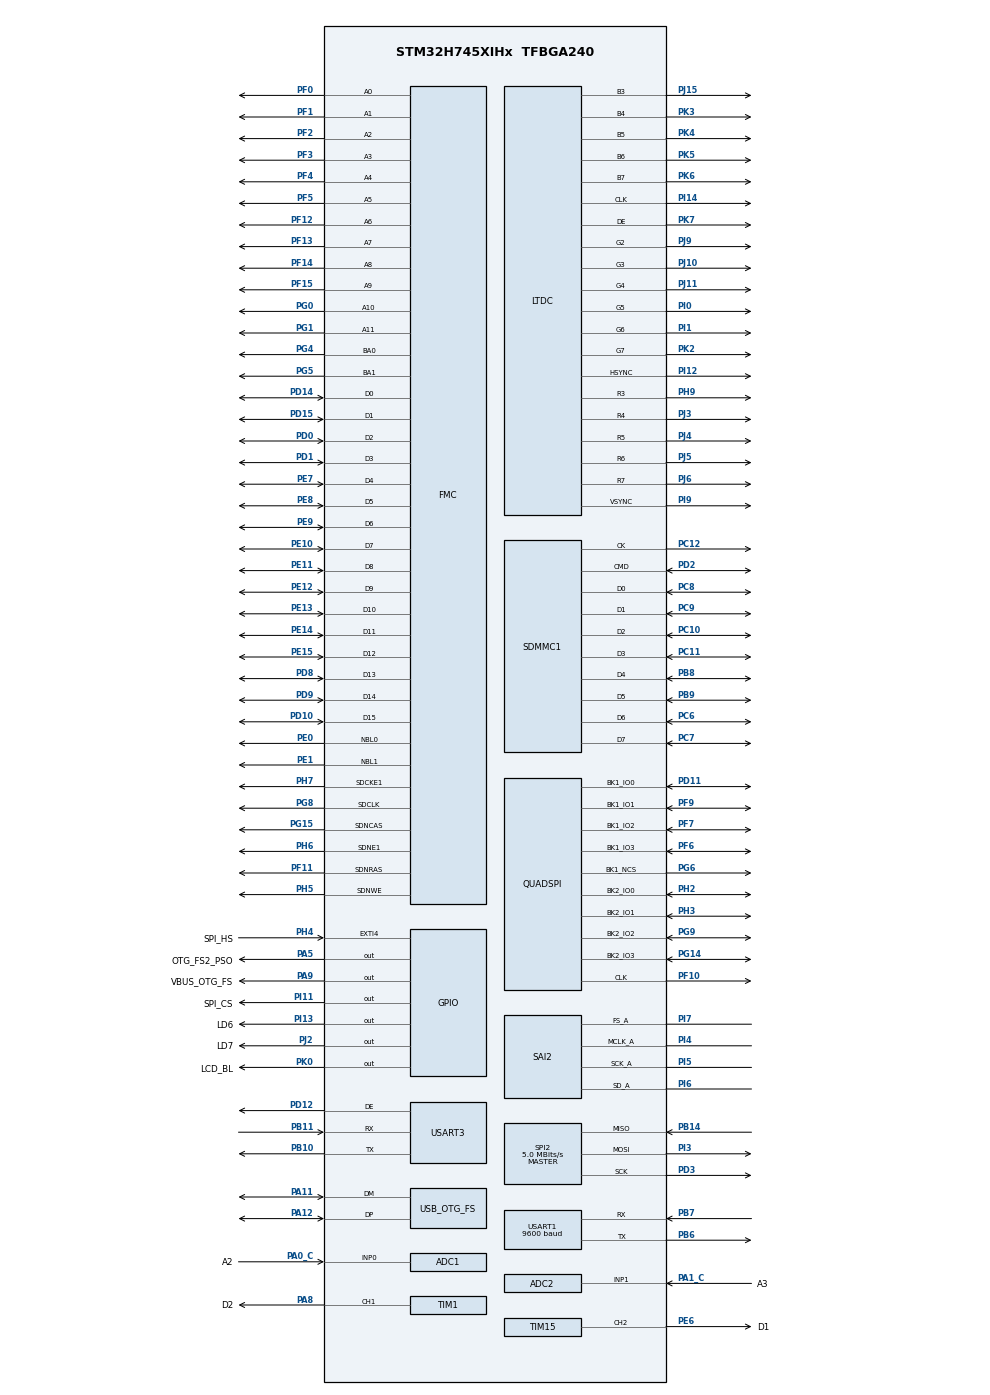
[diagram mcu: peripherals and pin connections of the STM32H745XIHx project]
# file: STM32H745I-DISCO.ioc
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ADC1.Channel-1\#ChannelRegularConversion=ADC_CHANNEL_0
ADC1.ClockPrescaler=ADC_CLOCK_ASYNC_DIV4
ADC1.ClockPrescalerADC3=ADC_CLOCK_ASYNC_DIV16
ADC1.ContinuousConvMode=ENABLE
ADC1.ConversionDataManagement=ADC_CONVERSIONDATA_DMA_CIRCULAR
ADC1.EnableAnalogWatchDog1=false
ADC1.NbrOfConversionFlag=1
ADC1.OffsetNumber-1\#ChannelRegularConversion=ADC_OFFSET_NONE
ADC1.OffsetSignedSaturation-1\#ChannelRegularConversion=DISABLE
ADC1.Overrun=ADC_OVR_DATA_PRESERVED
ADC1.Rank-1\#ChannelRegularConversion=1
ADC1.SamplingTime-1\#ChannelRegularConversion=ADC_SAMPLETIME_1CYCLE_5
ADC1.master=1
ADC2.Channel-0\#ChannelRegularConversion=ADC_CHANNEL_1
ADC2.ClockPrescaler=ADC_CLOCK_ASYNC_DIV4
ADC2.ClockPrescalerADC3=ADC_CLOCK_ASYNC_DIV16
ADC2.ContinuousConvMode=ENABLE
ADC2.ConversionDataManagement=ADC_CONVERSIONDATA_DMA_CIRCULAR
ADC2.EnableAnalogWatchDog1=false
ADC2.NbrOfConversionFlag=1
ADC2.OffsetNumber-0\#ChannelRegularConversion=ADC_OFFSET_NONE
ADC2.OffsetSignedSaturation-0\#ChannelRegularConversion=DISABLE
ADC2.Overrun=ADC_OVR_DATA_PRESERVED
ADC2.Rank-0\#ChannelRegularConversion=1
ADC2.SamplingTime-0\#ChannelRegularConversion=ADC_SAMPLETIME_1CYCLE_5
CORTEX_M7.AccessPermission-Cortex_Memory_Protection_Unit_Region0_Settings=MPU_REGION_FULL_ACCESS
CORTEX_M7.AccessPermission-Cortex_Memory_Protection_Unit_Region1_Settings=MPU_REGION_FULL_ACCESS
CORTEX_M7.BaseAddress-Cortex_Memory_Protection_Unit_Region0_Settings=0xD0000000
CORTEX_M7.BaseAddress-Cortex_Memory_Protection_Unit_Region1_Settings=0x90000000
CORTEX_M7.CPU_DCache=Disabled
CORTEX_M7.CPU_ICache=Enabled
CORTEX_M7.DisableExec-Cortex_Memory_Protection_Unit_Region0_Settings=MPU_INSTRUCTION_ACCESS_DISABLE
CORTEX_M7.DisableExec-Cortex_Memory_Protection_Unit_Region1_Settings=MPU_INSTRUCTION_ACCESS_DISABLE
CORTEX_M7.Enable-Cortex_Memory_Protection_Unit_Region0_Settings=MPU_REGION_ENABLE
CORTEX_M7.Enable-Cortex_Memory_Protection_Unit_Region1_Settings=MPU_REGION_ENABLE
CORTEX_M7.Enable-Cortex_Memory_Protection_Unit_Region2_Settings=__NULL
CORTEX_M7.Enable-Cortex_Memory_Protection_Unit_Region3_Settings=__NULL
CORTEX_M7.Enable-Cortex_Memory_Protection_Unit_Region4_Settings=__NULL
CORTEX_M7.IsBufferable-Cortex_Memory_Protection_Unit_Region0_Settings=MPU_ACCESS_BUFFERABLE
CORTEX_M7.IsBufferable-Cortex_Memory_Protection_Unit_Region1_Settings=MPU_ACCESS_BUFFERABLE
CORTEX_M7.IsCacheable-Cortex_Memory_Protection_Unit_Region0_Settings=MPU_ACCESS_CACHEABLE
CORTEX_M7.IsCacheable-Cortex_Memory_Protection_Unit_Region1_Settings=MPU_ACCESS_CACHEABLE
CORTEX_M7.IsShareable-Cortex_Memory_Protection_Unit_Region1_Settings=MPU_ACCESS_NOT_SHAREABLE
CORTEX_M7.MPU_Control=MPU_PRIVILEGED_DEFAULT
CORTEX_M7.Size-Cortex_Memory_Protection_Unit_Region0_Settings=MPU_REGION_SIZE_1MB
CORTEX_M7.Size-Cortex_Memory_Protection_Unit_Region1_Settings=MPU_REGION_SIZE_128MB
CORTEX_M7.default_mode_Activation=0
CortexM4.IPs=CORTEX_M4\:I,DEBUG,FATFS_M4\:I,FREERTOS_M4\:I,IWDG2\:I,OPENAMP_M4\:I,PDM2PCM_M4\:I,PWR,RCC,RESMGR_UTILITY,SYS_M4\:I,USB_DEVICE_M4\:I,USB_HOST_M4\:I,VREFBUF,WWDG2\:I,DMA,BDMA,MDMA,NVIC2\:I,GPIO
CortexM7.IPs=CORTEX_M7\:I,DEBUG\:I,FATFS_M7\:I,FREERTOS_M7\:I,IWDG1\:I,OPENAMP_M7\:I,PDM2PCM_M7\:I,PWR\:I,RCC\:I,RESMGR_UTILITY\:I,SYS\:I,USB_DEVICE_M7\:I,USB_HOST_M7\:I,VREFBUF\:I,WWDG1\:I,DMA\:I,BDMA\:I,MDMA\:I,NVIC1\:I,TIM6\:I,CRC\:I,LTDC\:I,DMA2D\:I,FMC\:I,QUADSPI\:I,STMicroelectronics.X-CUBE-TOUCHGFX.4.22.0_M7\:I,GPIO\:I,SDMMC1\:I,USB_OTG_FS\:I,SPI2\:I,USART1\:I,TIM1\:I,TIM15\:I,TIM14\:I,TIM7\:I,TIM17\:I,RTC\:I,TIM16\:I,USART3\:I,SAI2\:I,ADC1\:I,ADC2\:I,TIM5\:I
CortexM7.Pins=PA9,PI11,PI13,PK0,PH4,PA5,PJ2
DMA2D.ColorMode=DMA2D_OUTPUT_RGB565
DMA2D.Mode=DMA2D_R2M
Dma.ADC1.7.Direction=DMA_PERIPH_TO_MEMORY
Dma.ADC1.7.EventEnable=DISABLE
Dma.ADC1.7.FIFOMode=DMA_FIFOMODE_DISABLE
Dma.ADC1.7.Instance=DMA1_Stream6
Dma.ADC1.7.MemDataAlignment=DMA_MDATAALIGN_HALFWORD
Dma.ADC1.7.MemInc=DMA_MINC_ENABLE
Dma.ADC1.7.Mode=DMA_CIRCULAR
Dma.ADC1.7.PeriphDataAlignment=DMA_PDATAALIGN_HALFWORD
Dma.ADC1.7.PeriphInc=DMA_PINC_DISABLE
Dma.ADC1.7.Polarity=HAL_DMAMUX_REQ_GEN_RISING
Dma.ADC1.7.Priority=DMA_PRIORITY_LOW
Dma.ADC1.7.RequestNumber=1
Dma.ADC1.7.SignalID=NONE
Dma.ADC1.7.SyncEnable=DISABLE
Dma.ADC1.7.SyncPolarity=HAL_DMAMUX_SYNC_NO_EVENT
Dma.ADC1.7.SyncRequestNumber=1
Dma.ADC1.7.SyncSignalID=NONE
Dma.ADC2.8.Direction=DMA_PERIPH_TO_MEMORY
Dma.ADC2.8.EventEnable=DISABLE
Dma.ADC2.8.FIFOMode=DMA_FIFOMODE_DISABLE
Dma.ADC2.8.Instance=DMA1_Stream7
Dma.ADC2.8.MemDataAlignment=DMA_MDATAALIGN_HALFWORD
Dma.ADC2.8.MemInc=DMA_MINC_ENABLE
Dma.ADC2.8.Mode=DMA_CIRCULAR
Dma.ADC2.8.PeriphDataAlignment=DMA_PDATAALIGN_HALFWORD
Dma.ADC2.8.PeriphInc=DMA_PINC_DISABLE
Dma.ADC2.8.Polarity=HAL_DMAMUX_REQ_GEN_RISING
Dma.ADC2.8.Priority=DMA_PRIORITY_LOW
Dma.ADC2.8.RequestNumber=1
Dma.ADC2.8.SignalID=NONE
Dma.ADC2.8.SyncEnable=DISABLE
Dma.ADC2.8.SyncPolarity=HAL_DMAMUX_SYNC_NO_EVENT
Dma.ADC2.8.SyncRequestNumber=1
Dma.ADC2.8.SyncSignalID=NONE
Dma.Request0=USART1_RX
Dma.Request1=USART1_TX
Dma.Request2=USART3_RX
Dma.Request3=USART3_TX
Dma.Request4=SAI2_A
Dma.Request5=SPI2_RX
Dma.Request6=SPI2_TX
Dma.Request7=ADC1
Dma.Request8=ADC2
Dma.SAI2_A.4.Direction=DMA_MEMORY_TO_PERIPH
Dma.SAI2_A.4.EventEnable=DISABLE
Dma.SAI2_A.4.FIFOMode=DMA_FIFOMODE_DISABLE
Dma.SAI2_A.4.Instance=DMA2_Stream1
Dma.SAI2_A.4.MemDataAlignment=DMA_MDATAALIGN_HALFWORD
Dma.SAI2_A.4.MemInc=DMA_MINC_ENABLE
Dma.SAI2_A.4.Mode=DMA_CIRCULAR
Dma.SAI2_A.4.PeriphDataAlignment=DMA_PDATAALIGN_HALFWORD
Dma.SAI2_A.4.PeriphInc=DMA_PINC_DISABLE
Dma.SAI2_A.4.Polarity=HAL_DMAMUX_REQ_GEN_RISING
Dma.SAI2_A.4.Priority=DMA_PRIORITY_LOW
Dma.SAI2_A.4.RequestNumber=1
Dma.SAI2_A.4.SignalID=NONE
Dma.SAI2_A.4.SyncEnable=DISABLE
Dma.SAI2_A.4.SyncPolarity=HAL_DMAMUX_SYNC_NO_EVENT
Dma.SAI2_A.4.SyncRequestNumber=1
Dma.SAI2_A.4.SyncSignalID=NONE
Dma.SPI2_RX.5.Direction=DMA_PERIPH_TO_MEMORY
Dma.SPI2_RX.5.EventEnable=DISABLE
Dma.SPI2_RX.5.FIFOMode=DMA_FIFOMODE_ENABLE
Dma.SPI2_RX.5.FIFOThreshold=DMA_FIFO_THRESHOLD_FULL
Dma.SPI2_RX.5.Instance=DMA1_Stream2
Dma.SPI2_RX.5.MemBurst=DMA_MBURST_SINGLE
Dma.SPI2_RX.5.MemDataAlignment=DMA_MDATAALIGN_BYTE
Dma.SPI2_RX.5.MemInc=DMA_MINC_ENABLE
Dma.SPI2_RX.5.Mode=DMA_NORMAL
Dma.SPI2_RX.5.PeriphBurst=DMA_PBURST_SINGLE
Dma.SPI2_RX.5.PeriphDataAlignment=DMA_PDATAALIGN_BYTE
Dma.SPI2_RX.5.PeriphInc=DMA_PINC_DISABLE
Dma.SPI2_RX.5.Polarity=HAL_DMAMUX_REQ_GEN_RISING
Dma.SPI2_RX.5.Priority=DMA_PRIORITY_LOW
Dma.SPI2_RX.5.RequestNumber=1
Dma.SPI2_RX.5.SignalID=NONE
Dma.SPI2_RX.5.SyncEnable=DISABLE
Dma.SPI2_RX.5.SyncPolarity=HAL_DMAMUX_SYNC_NO_EVENT
Dma.SPI2_RX.5.SyncRequestNumber=1
Dma.SPI2_RX.5.SyncSignalID=NONE
Dma.SPI2_TX.6.Direction=DMA_MEMORY_TO_PERIPH
Dma.SPI2_TX.6.EventEnable=DISABLE
Dma.SPI2_TX.6.FIFOMode=DMA_FIFOMODE_ENABLE
Dma.SPI2_TX.6.FIFOThreshold=DMA_FIFO_THRESHOLD_FULL
Dma.SPI2_TX.6.Instance=DMA1_Stream5
Dma.SPI2_TX.6.MemBurst=DMA_MBURST_SINGLE
Dma.SPI2_TX.6.MemDataAlignment=DMA_MDATAALIGN_BYTE
Dma.SPI2_TX.6.MemInc=DMA_MINC_ENABLE
Dma.SPI2_TX.6.Mode=DMA_NORMAL
Dma.SPI2_TX.6.PeriphBurst=DMA_PBURST_SINGLE
Dma.SPI2_TX.6.PeriphDataAlignment=DMA_PDATAALIGN_BYTE
Dma.SPI2_TX.6.PeriphInc=DMA_PINC_DISABLE
Dma.SPI2_TX.6.Polarity=HAL_DMAMUX_REQ_GEN_RISING
Dma.SPI2_TX.6.Priority=DMA_PRIORITY_LOW
Dma.SPI2_TX.6.RequestNumber=1
Dma.SPI2_TX.6.SignalID=NONE
Dma.SPI2_TX.6.SyncEnable=DISABLE
Dma.SPI2_TX.6.SyncPolarity=HAL_DMAMUX_SYNC_NO_EVENT
Dma.SPI2_TX.6.SyncRequestNumber=1
Dma.SPI2_TX.6.SyncSignalID=NONE
Dma.USART1_RX.0.Direction=DMA_PERIPH_TO_MEMORY
Dma.USART1_RX.0.EventEnable=DISABLE
Dma.USART1_RX.0.FIFOMode=DMA_FIFOMODE_DISABLE
Dma.USART1_RX.0.Instance=DMA1_Stream0
Dma.USART1_RX.0.MemDataAlignment=DMA_MDATAALIGN_BYTE
Dma.USART1_RX.0.MemInc=DMA_MINC_ENABLE
Dma.USART1_RX.0.Mode=DMA_NORMAL
Dma.USART1_RX.0.PeriphDataAlignment=DMA_PDATAALIGN_BYTE
Dma.USART1_RX.0.PeriphInc=DMA_PINC_DISABLE
Dma.USART1_RX.0.Polarity=HAL_DMAMUX_REQ_GEN_RISING
Dma.USART1_RX.0.Priority=DMA_PRIORITY_LOW
Dma.USART1_RX.0.RequestNumber=1
Dma.USART1_RX.0.SignalID=NONE
Dma.USART1_RX.0.SyncEnable=DISABLE
Dma.USART1_RX.0.SyncPolarity=HAL_DMAMUX_SYNC_NO_EVENT
Dma.USART1_RX.0.SyncRequestNumber=1
Dma.USART1_RX.0.SyncSignalID=NONE
Dma.USART1_TX.1.Direction=DMA_MEMORY_TO_PERIPH
Dma.USART1_TX.1.EventEnable=DISABLE
Dma.USART1_TX.1.FIFOMode=DMA_FIFOMODE_DISABLE
Dma.USART1_TX.1.Instance=DMA1_Stream1
Dma.USART1_TX.1.MemDataAlignment=DMA_MDATAALIGN_BYTE
Dma.USART1_TX.1.MemInc=DMA_MINC_ENABLE
Dma.USART1_TX.1.Mode=DMA_NORMAL
Dma.USART1_TX.1.PeriphDataAlignment=DMA_PDATAALIGN_BYTE
Dma.USART1_TX.1.PeriphInc=DMA_PINC_DISABLE
Dma.USART1_TX.1.Polarity=HAL_DMAMUX_REQ_GEN_RISING
Dma.USART1_TX.1.Priority=DMA_PRIORITY_LOW
Dma.USART1_TX.1.RequestNumber=1
Dma.USART1_TX.1.SignalID=NONE
Dma.USART1_TX.1.SyncEnable=DISABLE
Dma.USART1_TX.1.SyncPolarity=HAL_DMAMUX_SYNC_NO_EVENT
Dma.USART1_TX.1.SyncRequestNumber=1
Dma.USART1_TX.1.SyncSignalID=NONE
Dma.USART3_RX.2.Direction=DMA_PERIPH_TO_MEMORY
Dma.USART3_RX.2.EventEnable=DISABLE
Dma.USART3_RX.2.FIFOMode=DMA_FIFOMODE_DISABLE
Dma.USART3_RX.2.Instance=DMA1_Stream3
Dma.USART3_RX.2.MemDataAlignment=DMA_MDATAALIGN_BYTE
Dma.USART3_RX.2.MemInc=DMA_MINC_ENABLE
Dma.USART3_RX.2.Mode=DMA_NORMAL
Dma.USART3_RX.2.PeriphDataAlignment=DMA_PDATAALIGN_BYTE
Dma.USART3_RX.2.PeriphInc=DMA_PINC_DISABLE
Dma.USART3_RX.2.Polarity=HAL_DMAMUX_REQ_GEN_RISING
Dma.USART3_RX.2.Priority=DMA_PRIORITY_LOW
Dma.USART3_RX.2.RequestNumber=1
Dma.USART3_RX.2.SignalID=NONE
Dma.USART3_RX.2.SyncEnable=DISABLE
Dma.USART3_RX.2.SyncPolarity=HAL_DMAMUX_SYNC_NO_EVENT
Dma.USART3_RX.2.SyncRequestNumber=1
Dma.USART3_RX.2.SyncSignalID=NONE
Dma.USART3_TX.3.Direction=DMA_MEMORY_TO_PERIPH
Dma.USART3_TX.3.EventEnable=DISABLE
Dma.USART3_TX.3.FIFOMode=DMA_FIFOMODE_DISABLE
Dma.USART3_TX.3.Instance=DMA1_Stream4
Dma.USART3_TX.3.MemDataAlignment=DMA_MDATAALIGN_BYTE
Dma.USART3_TX.3.MemInc=DMA_MINC_ENABLE
Dma.USART3_TX.3.Mode=DMA_NORMAL
Dma.USART3_TX.3.PeriphDataAlignment=DMA_PDATAALIGN_BYTE
Dma.USART3_TX.3.PeriphInc=DMA_PINC_DISABLE
Dma.USART3_TX.3.Polarity=HAL_DMAMUX_REQ_GEN_RISING
Dma.USART3_TX.3.Priority=DMA_PRIORITY_LOW
Dma.USART3_TX.3.RequestNumber=1
Dma.USART3_TX.3.SignalID=NONE
Dma.USART3_TX.3.SyncEnable=DISABLE
Dma.USART3_TX.3.SyncPolarity=HAL_DMAMUX_SYNC_NO_EVENT
Dma.USART3_TX.3.SyncRequestNumber=1
Dma.USART3_TX.3.SyncSignalID=NONE
FATFS_M7._CODE_PAGE=852
FATFS_M7._FS_EXFAT=1
FATFS_M7._FS_LOCK=4
FATFS_M7._FS_REENTRANT=1
FATFS_M7._FS_TINY=0
FATFS_M7._MAX_SS=512
FATFS_M7._MIN_SS=512
FATFS_M7._MULTI_PARTITION=0
FATFS_M7._USE_CHMOD=1
FATFS_M7._USE_EXPAND=1
FATFS_M7._USE_FASTSEEK=1
FATFS_M7._USE_FIND=1
FATFS_M7._USE_FORWARD=1
FATFS_M7._USE_LABEL=1
FATFS_M7._USE_LFN=3
FATFS_M7._USE_MUTEX=1
FATFS_M7._USE_TRIM=1
FATFS_M7._VOLUMES=2
FMC.CASLatency2=FMC_SDRAM_CAS_LATENCY_2
FMC.ExitSelfRefreshDelay2=6
FMC.LoadToActiveDelay2=2
FMC.RCDDelay2=2
FMC.RPDelay1=2
FMC.RPDelay2=2
FMC.ReadBurst2=FMC_SDRAM_RBURST_ENABLE
FMC.RowCycleDelay1=6
FMC.RowCycleDelay2=6
FMC.SDClockPeriod2=FMC_SDRAM_CLOCK_PERIOD_2
FMC.SelfRefreshTime2=4
FMC.WriteRecoveryTime2=2
FREERTOS_M7.Tasks01=AppTask,24,1536,App_Task,As weak,NULL,Dynamic,NULL,NULL;TouchGFXTask,24,4096,TouchGFX_Task,As weak,NULL,Dynamic,NULL,NULL
FREERTOS_M7.configENABLE_FPU=1
FREERTOS_M7.configMAX_TASK_NAME_LEN=48
FREERTOS_M7.configMINIMAL_STACK_SIZE=1024
FREERTOS_M7.configTOTAL_HEAP_SIZE=65536
FREERTOS_M7.configUSE_NEWLIB_REENTRANT=1
LTDC.ActiveH=272
LTDC.ActiveW=480
LTDC.Alpha0_L0=0
LTDC.Alpha_L0=255
LTDC.BlendingFactor1_L0=LTDC_BLENDING_FACTOR1_CA
LTDC.BlendingFactor2_L0=LTDC_BLENDING_FACTOR2_CA
LTDC.FBStartAdress_L0=0xD0000000
LTDC.HBP=13
LTDC.HFP=32
LTDC.HSync=41
LTDC.ImageHeight_L0=272
LTDC.ImageWidth_L0=480
LTDC.Layers=0
LTDC.PixelFormat_L0=LTDC_PIXEL_FORMAT_RGB565
LTDC.VBP=2
LTDC.VSync=10
LTDC.WindowX1_L0=480
LTDC.WindowY1_L0=272
Mcu.Family=STM32H7
Mcu.Name=STM32H745XIHx
Mcu.Package=TFBGA240
Mcu.UserConstants=COUNTER_TIM-CortexM7,$$_TIM5_IP_HANDLE_$$;COUNTER_1S-CortexM7,100000;DEBUG_PORT-CortexM7,$$_USART3_IP_HANDLE_$$;PRINTER_PORT-CortexM7,$$_USART1_IP_HANDLE_$$;EMMC-CortexM7,$$_SDMMC1_IP_HANDLE_$$;SLAVE_LINK-CortexM7,$$_SPI2_IP_HANDLE_$$;MICROTIME_TIM-CortexM7,$$_TIM7_IP_HANDLE_$$;DELAY_TIM-CortexM7,$$_TIM17_IP_HANDLE_$$;APB_CLOCK-CortexM7,200;DELAY_RESOLUTION-CortexM7,6
Mdma.MDMA_Channel10.Request0=SDMMC1_DMA_ENDBUFFER
Mdma.MDMA_Channel10.Request1=SDMMC1_COMMAND_END
Mdma.MDMA_Channel10.Request2=SDMMC1_END_DATA
Mdma.MDMA_Channel10.RequestsNb=3
Mdma.MDMA_Channel10.SDMMC1_COMMAND_END.1.BlockCount=0
Mdma.MDMA_Channel10.SDMMC1_COMMAND_END.1.BlockDataLength=0
Mdma.MDMA_Channel10.SDMMC1_COMMAND_END.1.BufferTransferLength=1
Mdma.MDMA_Channel10.SDMMC1_COMMAND_END.1.CircularMode=MDMA_LINEAR_LIST
Mdma.MDMA_Channel10.SDMMC1_COMMAND_END.1.DataAlignment=MDMA_DATAALIGN_PACKENABLE
Mdma.MDMA_Channel10.SDMMC1_COMMAND_END.1.DestBlockAddressOffset=0
Mdma.MDMA_Channel10.SDMMC1_COMMAND_END.1.DestBurst=MDMA_DEST_BURST_SINGLE
Mdma.MDMA_Channel10.SDMMC1_COMMAND_END.1.DestDataSize=MDMA_DEST_DATASIZE_BYTE
Mdma.MDMA_Channel10.SDMMC1_COMMAND_END.1.DestinationInc=MDMA_DEST_INC_BYTE
Mdma.MDMA_Channel10.SDMMC1_COMMAND_END.1.DstAddress=0
Mdma.MDMA_Channel10.SDMMC1_COMMAND_END.1.Endianness=MDMA_LITTLE_ENDIANNESS_PRESERVE
Mdma.MDMA_Channel10.SDMMC1_COMMAND_END.1.Instance=MDMA_Channel10
Mdma.MDMA_Channel10.SDMMC1_COMMAND_END.1.MaskAddress=0
Mdma.MDMA_Channel10.SDMMC1_COMMAND_END.1.MaskData=0
Mdma.MDMA_Channel10.SDMMC1_COMMAND_END.1.Priority=MDMA_PRIORITY_MEDIUM
Mdma.MDMA_Channel10.SDMMC1_COMMAND_END.1.Rank=Intermediate
Mdma.MDMA_Channel10.SDMMC1_COMMAND_END.1.SourceBlockAddressOffset=0
Mdma.MDMA_Channel10.SDMMC1_COMMAND_END.1.SourceBurst=MDMA_SOURCE_BURST_SINGLE
Mdma.MDMA_Channel10.SDMMC1_COMMAND_END.1.SourceDataSize=MDMA_SRC_DATASIZE_BYTE
Mdma.MDMA_Channel10.SDMMC1_COMMAND_END.1.SourceInc=MDMA_SRC_INC_BYTE
Mdma.MDMA_Channel10.SDMMC1_COMMAND_END.1.SrcAddress=0
Mdma.MDMA_Channel10.SDMMC1_COMMAND_END.1.TransferTriggerMode=MDMA_BLOCK_TRANSFER
Mdma.MDMA_Channel10.SDMMC1_COMMAND_END.1.node=node_mdma_channel10_sdmmc1_command_end_1
Mdma.MDMA_Channel10.SDMMC1_COMMAND_END.1.pNewNode=node_mdma_channel10_sdmmc1_command_end_1
Mdma.MDMA_Channel10.SDMMC1_DMA_ENDBUFFER.0.BlockCount=0
Mdma.MDMA_Channel10.SDMMC1_DMA_ENDBUFFER.0.BlockDataLength=0
Mdma.MDMA_Channel10.SDMMC1_DMA_ENDBUFFER.0.BufferTransferLength=1
Mdma.MDMA_Channel10.SDMMC1_DMA_ENDBUFFER.0.CircularMode=MDMA_LINEAR_LIST
Mdma.MDMA_Channel10.SDMMC1_DMA_ENDBUFFER.0.DataAlignment=MDMA_DATAALIGN_PACKENABLE
Mdma.MDMA_Channel10.SDMMC1_DMA_ENDBUFFER.0.DestBlockAddressOffset=0
Mdma.MDMA_Channel10.SDMMC1_DMA_ENDBUFFER.0.DestBurst=MDMA_DEST_BURST_SINGLE
Mdma.MDMA_Channel10.SDMMC1_DMA_ENDBUFFER.0.DestDataSize=MDMA_DEST_DATASIZE_BYTE
Mdma.MDMA_Channel10.SDMMC1_DMA_ENDBUFFER.0.DestinationInc=MDMA_DEST_INC_BYTE
Mdma.MDMA_Channel10.SDMMC1_DMA_ENDBUFFER.0.DstAddress=0
Mdma.MDMA_Channel10.SDMMC1_DMA_ENDBUFFER.0.Endianness=MDMA_LITTLE_ENDIANNESS_PRESERVE
Mdma.MDMA_Channel10.SDMMC1_DMA_ENDBUFFER.0.Instance=MDMA_Channel10
Mdma.MDMA_Channel10.SDMMC1_DMA_ENDBUFFER.0.MaskAddress=0
Mdma.MDMA_Channel10.SDMMC1_DMA_ENDBUFFER.0.MaskData=0
Mdma.MDMA_Channel10.SDMMC1_DMA_ENDBUFFER.0.Priority=MDMA_PRIORITY_MEDIUM
Mdma.MDMA_Channel10.SDMMC1_DMA_ENDBUFFER.0.Rank=First
Mdma.MDMA_Channel10.SDMMC1_DMA_ENDBUFFER.0.SourceBlockAddressOffset=0
Mdma.MDMA_Channel10.SDMMC1_DMA_ENDBUFFER.0.SourceBurst=MDMA_SOURCE_BURST_SINGLE
Mdma.MDMA_Channel10.SDMMC1_DMA_ENDBUFFER.0.SourceDataSize=MDMA_SRC_DATASIZE_BYTE
Mdma.MDMA_Channel10.SDMMC1_DMA_ENDBUFFER.0.SourceInc=MDMA_SRC_INC_BYTE
Mdma.MDMA_Channel10.SDMMC1_DMA_ENDBUFFER.0.SrcAddress=0
Mdma.MDMA_Channel10.SDMMC1_DMA_ENDBUFFER.0.TransferTriggerMode=MDMA_BLOCK_TRANSFER
Mdma.MDMA_Channel10.SDMMC1_END_DATA.2.BlockCount=0
Mdma.MDMA_Channel10.SDMMC1_END_DATA.2.BlockDataLength=0
Mdma.MDMA_Channel10.SDMMC1_END_DATA.2.BufferTransferLength=1
Mdma.MDMA_Channel10.SDMMC1_END_DATA.2.CircularMode=MDMA_LINEAR_LIST
Mdma.MDMA_Channel10.SDMMC1_END_DATA.2.DataAlignment=MDMA_DATAALIGN_PACKENABLE
Mdma.MDMA_Channel10.SDMMC1_END_DATA.2.DestBlockAddressOffset=0
Mdma.MDMA_Channel10.SDMMC1_END_DATA.2.DestBurst=MDMA_DEST_BURST_SINGLE
Mdma.MDMA_Channel10.SDMMC1_END_DATA.2.DestDataSize=MDMA_DEST_DATASIZE_BYTE
Mdma.MDMA_Channel10.SDMMC1_END_DATA.2.DestinationInc=MDMA_DEST_INC_BYTE
Mdma.MDMA_Channel10.SDMMC1_END_DATA.2.DstAddress=0
Mdma.MDMA_Channel10.SDMMC1_END_DATA.2.Endianness=MDMA_LITTLE_ENDIANNESS_PRESERVE
Mdma.MDMA_Channel10.SDMMC1_END_DATA.2.Instance=MDMA_Channel10
Mdma.MDMA_Channel10.SDMMC1_END_DATA.2.MaskAddress=0
Mdma.MDMA_Channel10.SDMMC1_END_DATA.2.MaskData=0
Mdma.MDMA_Channel10.SDMMC1_END_DATA.2.Priority=MDMA_PRIORITY_MEDIUM
Mdma.MDMA_Channel10.SDMMC1_END_DATA.2.Rank=Last
Mdma.MDMA_Channel10.SDMMC1_END_DATA.2.SourceBlockAddressOffset=0
Mdma.MDMA_Channel10.SDMMC1_END_DATA.2.SourceBurst=MDMA_SOURCE_BURST_SINGLE
Mdma.MDMA_Channel10.SDMMC1_END_DATA.2.SourceDataSize=MDMA_SRC_DATASIZE_BYTE
Mdma.MDMA_Channel10.SDMMC1_END_DATA.2.SourceInc=MDMA_SRC_INC_BYTE
Mdma.MDMA_Channel10.SDMMC1_END_DATA.2.SrcAddress=0
Mdma.MDMA_Channel10.SDMMC1_END_DATA.2.TransferTriggerMode=MDMA_BLOCK_TRANSFER
Mdma.MDMA_Channel10.SDMMC1_END_DATA.2.node=node_mdma_channel10_sdmmc1_end_data_2
Mdma.MDMA_Channel10.SDMMC1_END_DATA.2.pNewNode=node_mdma_channel10_sdmmc1_end_data_2
Mdma.RequestSet0=MDMA_Channel10
Mdma.RequestSetsNb=1
NVIC1.ADC_IRQn=true\:5\:0\:false\:false\:true\:true\:true\:true\:true
NVIC1.CRS_IRQn=true\:5\:0\:false\:false\:true\:false\:true\:true\:true
NVIC1.DMA1_Stream0_IRQn=true\:5\:0\:false\:false\:true\:true\:false\:true\:true
NVIC1.DMA1_Stream1_IRQn=true\:5\:0\:false\:false\:true\:true\:false\:true\:true
NVIC1.DMA1_Stream2_IRQn=true\:5\:0\:false\:false\:true\:true\:false\:true\:true
NVIC1.DMA1_Stream3_IRQn=true\:5\:0\:false\:false\:true\:true\:false\:true\:true
NVIC1.DMA1_Stream4_IRQn=true\:5\:0\:false\:false\:true\:true\:false\:true\:true
NVIC1.DMA1_Stream5_IRQn=true\:5\:0\:false\:false\:true\:true\:false\:true\:true
NVIC1.DMA1_Stream6_IRQn=true\:5\:0\:false\:false\:true\:true\:false\:true\:true
NVIC1.DMA1_Stream7_IRQn=true\:5\:0\:false\:false\:true\:true\:false\:true\:true
NVIC1.DMA2D_IRQn=true\:5\:0\:false\:false\:true\:true\:true\:true\:true
NVIC1.DMA2_Stream1_IRQn=true\:4\:0\:true\:false\:true\:false\:false\:true\:true
NVIC1.EXTI4_IRQn=true\:5\:0\:false\:false\:true\:true\:true\:true\:true
NVIC1.LTDC_IRQn=true\:5\:0\:false\:false\:true\:true\:true\:true\:true
NVIC1.MDMA_IRQn=true\:1\:0\:true\:false\:true\:false\:false\:true\:true
NVIC1.OTG_FS_EP1_IN_IRQn=true\:5\:0\:true\:false\:true\:true\:true\:true\:true
NVIC1.OTG_FS_EP1_OUT_IRQn=true\:5\:0\:true\:false\:true\:true\:true\:true\:true
NVIC1.OTG_FS_IRQn=true\:5\:0\:true\:false\:true\:true\:true\:true\:true
NVIC1.PriorityGroup=NVIC_PRIORITYGROUP_4
NVIC1.QUADSPI_IRQn=true\:5\:0\:false\:false\:true\:true\:true\:true\:true
NVIC1.RCC_IRQn=true\:5\:0\:false\:false\:true\:false\:true\:false\:true
NVIC1.SAI2_IRQn=true\:5\:0\:false\:false\:true\:true\:true\:true\:true
NVIC1.SDMMC1_IRQn=true\:5\:0\:false\:false\:true\:true\:true\:true\:true
NVIC1.SPI2_IRQn=true\:5\:0\:false\:false\:true\:true\:true\:true\:true
NVIC1.TIM17_IRQn=true\:5\:0\:false\:false\:true\:true\:true\:true\:true
NVIC1.TIM6_DAC_IRQn=true\:15\:0\:false\:false\:true\:false\:false\:true\:true
NVIC1.TIM7_IRQn=true\:0\:0\:true\:false\:true\:false\:true\:true\:true
NVIC1.TIM8_TRG_COM_TIM14_IRQn=true\:5\:0\:false\:false\:true\:true\:true\:true\:true
NVIC1.TimeBase=TIM6_DAC_IRQn
NVIC1.TimeBaseIP=TIM6
NVIC1.USART1_IRQn=true\:10\:0\:true\:false\:true\:true\:true\:true\:true
NVIC1.USART3_IRQn=true\:10\:0\:true\:false\:true\:true\:true\:true\:true
NVIC2.PriorityGroup=NVIC_PRIORITYGROUP_4
PA0_C.GPIO_Label=A2
PA0_C.PinAttribute=CortexM7
PA0_C.Signal=ADCx_INP0
PA11.GPIO_Speed=GPIO_SPEED_FREQ_MEDIUM
PA11.Mode=Host_Only
PA11.PinAttribute=CortexM7
PA11.Signal=USB_OTG_FS_DM
PA12.GPIO_Speed=GPIO_SPEED_FREQ_MEDIUM
PA12.Mode=Host_Only
PA12.PinAttribute=CortexM7
PA12.Signal=USB_OTG_FS_DP
PA1_C.GPIO_Label=A3
PA1_C.PinAttribute=CortexM7
PA1_C.Signal=ADCx_INP1
PA5.GPIO_Label=OTG_FS2_PSO
PA5.PinAttribute=CortexM7
PA5.PinState=GPIO_PIN_SET
PA5.Signal=GPIO_Output
PA8.GPIO_Label=D2
PA8.PinAttribute=CortexM7
PA8.Signal=S_TIM1_CH1
PA9.GPIO_Label=VBUS_OTG_FS
PA9.PinAttribute=CortexM7
PA9.PinState=GPIO_PIN_SET
PA9.Signal=GPIO_Output
PB10.Mode=Asynchronous
PB10.PinAttribute=CortexM7
PB10.Signal=USART3_TX
PB11.Mode=Asynchronous
PB11.PinAttribute=CortexM7
PB11.Signal=USART3_RX
PB14.Mode=Full_Duplex_Master
PB14.PinAttribute=CortexM7
PB14.Signal=SPI2_MISO
PB6.Mode=Asynchronous
PB6.PinAttribute=CortexM7
PB6.Signal=USART1_TX
PB7.Mode=Asynchronous
PB7.PinAttribute=CortexM7
PB7.Signal=USART1_RX
PB8.Mode=mmc_8_bits_Wide_bus
PB8.PinAttribute=CortexM7
PB8.Signal=SDMMC1_D4
PB9.Mode=mmc_8_bits_Wide_bus
PB9.PinAttribute=CortexM7
PB9.Signal=SDMMC1_D5
PC10.Mode=mmc_8_bits_Wide_bus
PC10.PinAttribute=CortexM7
PC10.Signal=SDMMC1_D2
PC11.Mode=mmc_8_bits_Wide_bus
PC11.PinAttribute=CortexM7
PC11.Signal=SDMMC1_D3
PC12.Mode=mmc_8_bits_Wide_bus
PC12.PinAttribute=CortexM7
PC12.Signal=SDMMC1_CK
PC14-OSC32_IN\ (OSC32_IN).Mode=LSE-External-Oscillator
PC14-OSC32_IN\ (OSC32_IN).PinAttribute=CortexM7
PC14-OSC32_IN\ (OSC32_IN).Signal=RCC_OSC32_IN
PC15-OSC32_OUT\ (OSC32_OUT).Mode=LSE-External-Oscillator
PC15-OSC32_OUT\ (OSC32_OUT).PinAttribute=CortexM7
PC15-OSC32_OUT\ (OSC32_OUT).Signal=RCC_OSC32_OUT
PC2_C.GPIO_Label=A4
PC2_C.PinAttribute=CortexM7
PC2_C.Signal=ADC3_INP0
PC3_C.GPIO_Label=A5
PC3_C.PinAttribute=CortexM7
PC3_C.Signal=ADC3_INP1
PC6.Mode=mmc_8_bits_Wide_bus
PC6.PinAttribute=CortexM7
PC6.Signal=SDMMC1_D6
PC7.Mode=mmc_8_bits_Wide_bus
PC7.PinAttribute=CortexM7
PC7.Signal=SDMMC1_D7
PC8.Mode=mmc_8_bits_Wide_bus
PC8.PinAttribute=CortexM7
PC8.Signal=SDMMC1_D0
PC9.Mode=mmc_8_bits_Wide_bus
PC9.PinAttribute=CortexM7
PC9.Signal=SDMMC1_D1
PD0.PinAttribute=CortexM7
PD0.Signal=FMC_D2_DA2
PD1.PinAttribute=CortexM7
PD1.Signal=FMC_D3_DA3
PD10.PinAttribute=CortexM7
PD10.Signal=FMC_D15_DA15
PD11.GPIO_Speed=GPIO_SPEED_FREQ_VERY_HIGH
PD11.Mode=Dual_Bank
PD11.PinAttribute=CortexM7
PD11.Signal=QUADSPI_BK1_IO0
PD12.Mode=Hardware Flow Control (RS485)
PD12.PinAttribute=CortexM7
PD12.Signal=USART3_DE
PD14.PinAttribute=CortexM7
PD14.Signal=FMC_D0_DA0
PD15.PinAttribute=CortexM7
PD15.Signal=FMC_D1_DA1
PD2.Mode=mmc_8_bits_Wide_bus
PD2.PinAttribute=CortexM7
PD2.Signal=SDMMC1_CMD
PD3.Mode=Full_Duplex_Master
PD3.PinAttribute=CortexM7
PD3.Signal=SPI2_SCK
PD8.PinAttribute=CortexM7
PD8.Signal=FMC_D13_DA13
PD9.PinAttribute=CortexM7
PD9.Signal=FMC_D14_DA14
PE0.PinAttribute=CortexM7
PE0.Signal=FMC_NBL0
PE1.PinAttribute=CortexM7
PE1.Signal=FMC_NBL1
PE10.PinAttribute=CortexM7
PE10.Signal=FMC_D7_DA7
PE11.PinAttribute=CortexM7
PE11.Signal=FMC_D8_DA8
PE12.PinAttribute=CortexM7
PE12.Signal=FMC_D9_DA9
PE13.PinAttribute=CortexM7
PE13.Signal=FMC_D10_DA10
PE14.PinAttribute=CortexM7
PE14.Signal=FMC_D11_DA11
PE15.PinAttribute=CortexM7
PE15.Signal=FMC_D12_DA12
PE6.GPIO_Label=D1
PE6.PinAttribute=CortexM7
PE6.Signal=S_TIM15_CH2
PE7.PinAttribute=CortexM7
PE7.Signal=FMC_D4_DA4
PE8.PinAttribute=CortexM7
PE8.Signal=FMC_D5_DA5
PE9.PinAttribute=CortexM7
PE9.Signal=FMC_D6_DA6
PF0.PinAttribute=CortexM7
PF0.Signal=FMC_A0
PF1.PinAttribute=CortexM7
PF1.Signal=FMC_A1
PF10.GPIO_Speed=GPIO_SPEED_FREQ_VERY_HIGH
PF10.Mode=Dual_Bank
PF10.PinAttribute=CortexM7
PF10.Signal=QUADSPI_CLK
PF11.PinAttribute=CortexM7
PF11.Signal=FMC_SDNRAS
PF12.PinAttribute=CortexM7
PF12.Signal=FMC_A6
PF13.PinAttribute=CortexM7
PF13.Signal=FMC_A7
PF14.PinAttribute=CortexM7
PF14.Signal=FMC_A8
PF15.PinAttribute=CortexM7
PF15.Signal=FMC_A9
PF2.PinAttribute=CortexM7
PF2.Signal=FMC_A2
PF3.PinAttribute=CortexM7
PF3.Signal=FMC_A3
PF4.PinAttribute=CortexM7
PF4.Signal=FMC_A4
PF5.PinAttribute=CortexM7
PF5.Signal=FMC_A5
PF6.GPIO_Speed=GPIO_SPEED_FREQ_VERY_HIGH
PF6.Mode=Dual_Bank
PF6.PinAttribute=CortexM7
PF6.Signal=QUADSPI_BK1_IO3
PF7.GPIO_Speed=GPIO_SPEED_FREQ_VERY_HIGH
PF7.Mode=Dual_Bank
PF7.PinAttribute=CortexM7
PF7.Signal=QUADSPI_BK1_IO2
PF9.GPIO_Speed=GPIO_SPEED_FREQ_VERY_HIGH
PF9.Mode=Dual_Bank
PF9.PinAttribute=CortexM7
PF9.Signal=QUADSPI_BK1_IO1
PG0.PinAttribute=CortexM7
PG0.Signal=FMC_A10
PG1.PinAttribute=CortexM7
PG1.Signal=FMC_A11
PG14.GPIO_Speed=GPIO_SPEED_FREQ_VERY_HIGH
PG14.Mode=Dual_Bank
PG14.PinAttribute=CortexM7
PG14.Signal=QUADSPI_BK2_IO3
PG15.PinAttribute=CortexM7
PG15.Signal=FMC_SDNCAS
PG4.PinAttribute=CortexM7
PG4.Signal=FMC_A14_BA0
PG5.PinAttribute=CortexM7
PG5.Signal=FMC_A15_BA1
PG6.GPIO_PuPd=GPIO_PULLUP
PG6.GPIO_Speed=GPIO_SPEED_FREQ_VERY_HIGH
PG6.Mode=Enable Chip Select 1 for both banks
PG6.PinAttribute=CortexM7
PG6.Signal=QUADSPI_BK1_NCS
PG8.PinAttribute=CortexM7
PG8.Signal=FMC_SDCLK
PG9.GPIO_Speed=GPIO_SPEED_FREQ_VERY_HIGH
PG9.Mode=Dual_Bank
PG9.PinAttribute=CortexM7
PG9.Signal=QUADSPI_BK2_IO2
PH0-OSC_IN\ (PH0).Mode=HSE-External-Oscillator
PH0-OSC_IN\ (PH0).PinAttribute=CortexM7
PH0-OSC_IN\ (PH0).Signal=RCC_OSC_IN
PH1-OSC_OUT\ (PH1).Mode=HSE-External-Oscillator
PH1-OSC_OUT\ (PH1).PinAttribute=CortexM7
PH1-OSC_OUT\ (PH1).Signal=RCC_OSC_OUT
PH2.GPIO_Speed=GPIO_SPEED_FREQ_VERY_HIGH
PH2.Mode=Dual_Bank
PH2.PinAttribute=CortexM7
PH2.Signal=QUADSPI_BK2_IO0
PH3.GPIO_Speed=GPIO_SPEED_FREQ_VERY_HIGH
PH3.Mode=Dual_Bank
PH3.PinAttribute=CortexM7
PH3.Signal=QUADSPI_BK2_IO1
PH4.GPIO_Label=SPI_HS
PH4.GPIO_ModeDefaultEXTI=GPIO_MODE_IT_RISING_FALLING
PH4.GPIO_PuPd=GPIO_PULLDOWN
PH4.PinAttribute=CortexM7
PH4.Signal=GPXTI4
PH5.PinAttribute=CortexM7
PH5.Signal=FMC_SDNWE
PH6.Mode=SdramChipSelect2_2
PH6.PinAttribute=CortexM7
PH6.Signal=FMC_SDNE1
PH7.Mode=SdramChipSelect2_2
PH7.PinAttribute=CortexM7
PH7.Signal=FMC_SDCKE1
PH9.GPIO_Speed=GPIO_SPEED_FREQ_HIGH
PH9.Mode=RGB565
PH9.PinAttribute=CortexM7
PH9.Signal=LTDC_R3
PI0.GPIO_Speed=GPIO_SPEED_FREQ_HIGH
PI0.Mode=RGB565
PI0.PinAttribute=CortexM7
PI0.Signal=LTDC_G5
PI1.GPIO_Speed=GPIO_SPEED_FREQ_HIGH
PI1.Mode=RGB565
PI1.PinAttribute=CortexM7
PI1.Signal=LTDC_G6
PI11.GPIO_Label=SPI_CS
PI11.PinAttribute=CortexM7
PI11.Signal=GPIO_Output
PI12.GPIO_Speed=GPIO_SPEED_FREQ_HIGH
PI12.Mode=RGB565
PI12.PinAttribute=CortexM7
PI12.Signal=LTDC_HSYNC
PI13.GPIO_Label=LD6
PI13.PinAttribute=CortexM7
PI13.PinState=GPIO_PIN_SET
PI13.Signal=GPIO_Output
PI14.GPIO_Speed=GPIO_SPEED_FREQ_HIGH
PI14.Mode=RGB565
PI14.PinAttribute=CortexM7
PI14.Signal=LTDC_CLK
PI15.GPIO_Speed=GPIO_SPEED_FREQ_HIGH
PI15.PinAttribute=CortexM7
PI15.Signal=LTDC_R0
PI3.Mode=Full_Duplex_Master
PI3.PinAttribute=CortexM7
PI3.Signal=SPI2_MOSI
PI4.GPIO_Speed=GPIO_SPEED_FREQ_VERY_HIGH
PI4.Mode=SAI_A_MasterWithClock
PI4.PinAttribute=CortexM7
PI4.Signal=SAI2_MCLK_A
PI5.GPIO_Speed=GPIO_SPEED_FREQ_VERY_HIGH
PI5.Mode=SAI_A_MasterWithClock
PI5.PinAttribute=CortexM7
PI5.Signal=SAI2_SCK_A
PI6.GPIO_Speed=GPIO_SPEED_FREQ_VERY_HIGH
PI6.Mode=SAI_A_MasterWithClock
PI6.PinAttribute=CortexM7
PI6.Signal=SAI2_SD_A
PI7.GPIO_Speed=GPIO_SPEED_FREQ_VERY_HIGH
PI7.Mode=SAI_A_MasterWithClock
PI7.PinAttribute=CortexM7
PI7.Signal=SAI2_FS_A
PI9.GPIO_Speed=GPIO_SPEED_FREQ_HIGH
PI9.Mode=RGB565
PI9.PinAttribute=CortexM7
PI9.Signal=LTDC_VSYNC
PJ0.GPIO_Speed=GPIO_SPEED_FREQ_HIGH
PJ0.PinAttribute=CortexM7
PJ0.Signal=LTDC_R1
PJ1.GPIO_Speed=GPIO_SPEED_FREQ_HIGH
PJ1.PinAttribute=CortexM7
PJ1.Signal=LTDC_R2
PJ10.GPIO_Speed=GPIO_SPEED_FREQ_HIGH
PJ10.Mode=RGB565
PJ10.PinAttribute=CortexM7
PJ10.Signal=LTDC_G3
PJ11.GPIO_Speed=GPIO_SPEED_FREQ_HIGH
PJ11.Mode=RGB565
PJ11.PinAttribute=CortexM7
PJ11.Signal=LTDC_G4
PJ12.GPIO_Speed=GPIO_SPEED_FREQ_HIGH
PJ12.PinAttribute=CortexM7
PJ12.Signal=LTDC_B0
PJ13.GPIO_Speed=GPIO_SPEED_FREQ_HIGH
PJ13.PinAttribute=CortexM7
PJ13.Signal=LTDC_B1
PJ14.GPIO_Speed=GPIO_SPEED_FREQ_HIGH
PJ14.PinAttribute=CortexM7
PJ14.Signal=LTDC_B2
PJ15.GPIO_Speed=GPIO_SPEED_FREQ_HIGH
PJ15.Mode=RGB565
PJ15.PinAttribute=CortexM7
PJ15.Signal=LTDC_B3
PJ2.GPIO_Label=LD7
PJ2.PinAttribute=CortexM7
PJ2.PinState=GPIO_PIN_SET
PJ2.Signal=GPIO_Output
PJ3.GPIO_Speed=GPIO_SPEED_FREQ_HIGH
PJ3.Mode=RGB565
PJ3.PinAttribute=CortexM7
PJ3.Signal=LTDC_R4
PJ4.GPIO_Speed=GPIO_SPEED_FREQ_HIGH
PJ4.Mode=RGB565
PJ4.PinAttribute=CortexM7
PJ4.Signal=LTDC_R5
PJ5.GPIO_Speed=GPIO_SPEED_FREQ_HIGH
PJ5.Mode=RGB565
PJ5.PinAttribute=CortexM7
PJ5.Signal=LTDC_R6
PJ6.GPIO_Speed=GPIO_SPEED_FREQ_HIGH
PJ6.Mode=RGB565
PJ6.PinAttribute=CortexM7
PJ6.Signal=LTDC_R7
PJ7.GPIO_Speed=GPIO_SPEED_FREQ_HIGH
PJ7.PinAttribute=CortexM7
PJ7.Signal=LTDC_G0
PJ8.GPIO_Speed=GPIO_SPEED_FREQ_HIGH
PJ8.PinAttribute=CortexM7
PJ8.Signal=LTDC_G1
PJ9.GPIO_Speed=GPIO_SPEED_FREQ_HIGH
PJ9.Mode=RGB565
PJ9.PinAttribute=CortexM7
PJ9.Signal=LTDC_G2
PK0.GPIO_Label=LCD_BL
PK0.PinAttribute=CortexM7
PK0.Signal=GPIO_Output
PK2.GPIO_Speed=GPIO_SPEED_FREQ_HIGH
PK2.Mode=RGB565
PK2.PinAttribute=CortexM7
PK2.Signal=LTDC_G7
PK3.GPIO_Speed=GPIO_SPEED_FREQ_HIGH
PK3.Mode=RGB565
PK3.PinAttribute=CortexM7
PK3.Signal=LTDC_B4
PK4.GPIO_Speed=GPIO_SPEED_FREQ_HIGH
PK4.Mode=RGB565
PK4.PinAttribute=CortexM7
PK4.Signal=LTDC_B5
PK5.GPIO_Speed=GPIO_SPEED_FREQ_HIGH
PK5.Mode=RGB565
PK5.PinAttribute=CortexM7
PK5.Signal=LTDC_B6
PK6.GPIO_Speed=GPIO_SPEED_FREQ_HIGH
PK6.Mode=RGB565
PK6.PinAttribute=CortexM7
PK6.Signal=LTDC_B7
PK7.GPIO_Speed=GPIO_SPEED_FREQ_HIGH
PK7.Mode=RGB565
PK7.PinAttribute=CortexM7
PK7.Signal=LTDC_DE
ProjectManager.HeapSize=M4-0x200,M7-0x1000
ProjectManager.StackSize=M4-0x400,M7-0x1000
ProjectManager.TargetToolchain=STM32CubeIDE
QUADSPI.ChipSelectHighTime=QSPI_CS_HIGH_TIME_3_CYCLE
QUADSPI.ClockPrescaler=1
QUADSPI.FlashSize=26
QUADSPI.SampleShifting=QSPI_SAMPLE_SHIFTING_HALFCYCLE
RCC.ADCCLockSelection=RCC_ADCCLKSOURCE_CLKP
RCC.ADCFreq_Value=4000000
RCC.APB1Freq_Value=100000000
RCC.APB2Freq_Value=100000000
RCC.APB3Freq_Value=100000000
RCC.APB4Freq_Value=100000000
RCC.CKPERSourceSelection=RCC_CLKPSOURCE_CSI
RCC.CortexFreq_Value=400000000
RCC.D1PPRE=RCC_APB3_DIV2
RCC.D2PPRE1=RCC_APB1_DIV2
RCC.D2PPRE2=RCC_APB2_DIV2
RCC.D3PPRE=RCC_APB4_DIV2
RCC.DIVM1=5
RCC.DIVM2=25
RCC.DIVM3=5
RCC.DIVN1=160
RCC.DIVN2=429
RCC.DIVN3=160
RCC.DIVP2=38
RCC.DIVP3=20
RCC.DIVQ1=4
RCC.DIVQ2=1
RCC.DIVR2=1
RCC.DIVR3=83
RCC.HCLKFreq_Value=200000000
RCC.HPRE=RCC_HCLK_DIV2
RCC.HSE_VALUE=25000000
RCC.PLL2FRACN=100
RCC.PLLSourceVirtual=RCC_PLLSOURCE_HSE
RCC.PWR_Regulator_Voltage_Scale=PWR_REGULATOR_VOLTAGE_SCALE1
RCC.RTCClockSelection=RCC_RTCCLKSOURCE_LSE
RCC.SAI1CLockSelection=RCC_SAI1CLKSOURCE_PLL2
RCC.SAI23CLockSelection=RCC_SAI23CLKSOURCE_PLL2
RCC.SPI123CLockSelection=RCC_SPI123CLKSOURCE_PLL3
RCC.SYSCLKFreq_VALUE=400000000
RCC.SYSCLKSource=RCC_SYSCLKSOURCE_PLLCLK
RCC.USBCLockSelection=RCC_USBCLKSOURCE_HSI48
RCC.USBFreq_Value=48000000
SAI2.ActiveFrameLength-SAI_A_MasterWithClock=64
SAI2.AudioFrequency-SAI_A_MasterWithClock=SAI_AUDIO_FREQUENCY_22K
SAI2.ClockStrobing-SAI_A_MasterWithClock=SAI_CLOCKSTROBING_RISINGEDGE
SAI2.DataSize-SAI_A_MasterWithClock=SAI_DATASIZE_16
SAI2.ErrorAudioFreq-SAI_A_MasterWithClock=0.22 %
SAI2.FIFOThreshold-SAI_A_MasterWithClock=SAI_FIFOTHRESHOLD_EMPTY
SAI2.FSDefinition-SAI_A_MasterWithClock=SAI_FS_CHANNEL_IDENTIFICATION
SAI2.FSOffset-SAI_A_MasterWithClock=SAI_FS_BEFOREFIRSTBIT
SAI2.FrameLength-SAI_A_MasterWithClock=128
SAI2.Instance-SAI_A_MasterWithClock=SAI$Index_Block_A
SAI2.MClockEnable-SAI_A_MasterWithClock=SAI_MASTERCLOCK_ENABLE
SAI2.MonoStereoMode-SAI_A_MasterWithClock=SAI_STEREOMODE
SAI2.OutputDrive-SAI_A_MasterWithClock=SAI_OUTPUTDRIVE_ENABLE
SAI2.RealAudioFreq-SAI_A_MasterWithClock=22.05 KHz
SAI2.SlotActive-SAI_A_MasterWithClock=0x0000FFFF
SAI2.SlotNumber-SAI_A_MasterWithClock=2
SAI2.VirtualMode-SAI_A_MasterWithClock=VM_MASTER
SAI2.VirtualSlotActive-SAI_A_MasterWithClock=SAI_SLOTACTIVE_ALL
SDMMC1.ClockDiv=2
SDMMC1.HardwareFlowControl=SDMMC_HARDWARE_FLOW_CONTROL_ENABLE
SDMMC1.TransceiverPresent=SDMMC_TRANSCEIVER_NOT_PRESENT
SH.ADCx_INP0.0=ADC1_INP0,IN0-Single-Ended
SH.ADCx_INP1.0=ADC2_INP1,IN1-Single-Ended
SH.FMC_A0.0=FMC_A0,12b-sda2
SH.FMC_A1.0=FMC_A1,12b-sda2
SH.FMC_A10.0=FMC_A10,12b-sda2
SH.FMC_A11.0=FMC_A11,12b-sda2
SH.FMC_A14_BA0.0=FMC_BA0,FourSdramBanks2
SH.FMC_A15_BA1.0=FMC_BA1,FourSdramBanks2
SH.FMC_A2.0=FMC_A2,12b-sda2
SH.FMC_A3.0=FMC_A3,12b-sda2
SH.FMC_A4.0=FMC_A4,12b-sda2
SH.FMC_A5.0=FMC_A5,12b-sda2
SH.FMC_A6.0=FMC_A6,12b-sda2
SH.FMC_A7.0=FMC_A7,12b-sda2
SH.FMC_A8.0=FMC_A8,12b-sda2
SH.FMC_A9.0=FMC_A9,12b-sda2
SH.FMC_D0_DA0.0=FMC_D0,sd-16b-d2
SH.FMC_D10_DA10.0=FMC_D10,sd-16b-d2
SH.FMC_D11_DA11.0=FMC_D11,sd-16b-d2
SH.FMC_D12_DA12.0=FMC_D12,sd-16b-d2
SH.FMC_D13_DA13.0=FMC_D13,sd-16b-d2
SH.FMC_D14_DA14.0=FMC_D14,sd-16b-d2
SH.FMC_D15_DA15.0=FMC_D15,sd-16b-d2
SH.FMC_D1_DA1.0=FMC_D1,sd-16b-d2
SH.FMC_D2_DA2.0=FMC_D2,sd-16b-d2
SH.FMC_D3_DA3.0=FMC_D3,sd-16b-d2
SH.FMC_D4_DA4.0=FMC_D4,sd-16b-d2
SH.FMC_D5_DA5.0=FMC_D5,sd-16b-d2
SH.FMC_D6_DA6.0=FMC_D6,sd-16b-d2
SH.FMC_D7_DA7.0=FMC_D7,sd-16b-d2
SH.FMC_D8_DA8.0=FMC_D8,sd-16b-d2
SH.FMC_D9_DA9.0=FMC_D9,sd-16b-d2
SH.FMC_NBL0.0=FMC_NBL0,Sd2ByteEnable2
SH.FMC_NBL1.0=FMC_NBL1,Sd2ByteEnable2
SH.FMC_SDCLK.0=FMC_SDCLK,12b-sda2
SH.FMC_SDNCAS.0=FMC_SDNCAS,12b-sda2
SH.FMC_SDNRAS.0=FMC_SDNRAS,12b-sda2
SH.FMC_SDNWE.0=FMC_SDNWE,12b-sda2
SH.S_TIM15_CH2.0=TIM15_CH2,PWM Generation2 CH2
SH.S_TIM1_CH1.0=TIM1_CH1,PWM Generation1 CH1
SPI2.BaudRatePrescaler=SPI_BAUDRATEPRESCALER_8
SPI2.CRCCalculation=SPI_CRCCALCULATION_DISABLE
SPI2.CalculateBaudRate=5.0 MBits/s
SPI2.DataSize=SPI_DATASIZE_8BIT
SPI2.Direction=SPI_DIRECTION_2LINES
SPI2.MasterInterDataIdleness=SPI_MASTER_INTERDATA_IDLENESS_00CYCLE
SPI2.MasterKeepIOState=SPI_MASTER_KEEP_IO_STATE_ENABLE
SPI2.MasterReceiverAutoSusp=SPI_MASTER_RX_AUTOSUSP_DISABLE
SPI2.MasterSSIdleness=SPI_MASTER_SS_IDLENESS_00CYCLE
SPI2.Mode=SPI_MODE_MASTER
SPI2.NSSPMode=SPI_NSS_PULSE_DISABLE
SPI2.TIMode=SPI_TIMODE_DISABLE
SPI2.VirtualType=VM_MASTER
STMicroelectronics.X-CUBE-TOUCHGFX.4.22.0_IsPackSelfContextualization=true
STMicroelectronics.X-CUBE-TOUCHGFX.4.22.0_M7.ApplicationCcGraphicsJjApplication=TouchGFXOoGenerator
STMicroelectronics.X-CUBE-TOUCHGFX.4.22.0_M7.tgfx_address1=0xD0000000
STMicroelectronics.X-CUBE-TOUCHGFX.4.22.0_M7.tgfx_address2=0xD0200000
STMicroelectronics.X-CUBE-TOUCHGFX.4.22.0_M7.tgfx_buffering_strategy=Double
STMicroelectronics.X-CUBE-TOUCHGFX.4.22.0_M7.tgfx_custom_height=272
STMicroelectronics.X-CUBE-TOUCHGFX.4.22.0_M7.tgfx_datareader=Disabled
STMicroelectronics.X-CUBE-TOUCHGFX.4.22.0_M7.tgfx_display_interface=disp_ltdc
STMicroelectronics.X-CUBE-TOUCHGFX.4.22.0_M7.tgfx_hardware_accelerator=dma_2d
STMicroelectronics.X-CUBE-TOUCHGFX.4.22.0_M7.tgfx_location=By Address
STMicroelectronics.X-CUBE-TOUCHGFX.4.22.0_M7.tgfx_vector_rendering=Enabled
STMicroelectronics.X-CUBE-TOUCHGFX.4.22.0_M7.tgfx_vsync=vsync_ltdc
SYS.userName=SYS_M7
TIM1.Channel-PWM\ Generation1\ CH1=TIM_CHANNEL_1
TIM1.Period=1000-1
TIM1.Prescaler=2-1
TIM14.Period=1000-1
TIM14.Prescaler=200-1
TIM15.Channel-PWM\ Generation2\ CH2=TIM_CHANNEL_2
TIM15.Period=1000-1
TIM15.Prescaler=2-1
TIM17.Period=1000-1
TIM17.Prescaler=200-1
TIM5.Prescaler=2000-1
TIM7.Prescaler=2-1
USART1.BaudRate=9600
USART1.Mode=MODE_TX_RX
USART1.VirtualMode-Asynchronous=VM_ASYNC
USART3.VirtualMode-Asynchronous=VM_ASYNC
USART3.VirtualMode-Hardware\ Flow\ Control\ (RS485)=VM_ASYNC
USB_HOST.BSP.number=1
USB_HOST0.BSP.STBoard=false
USB_HOST0.BSP.api=Unknown
USB_HOST0.BSP.instance=PA9
USB_HOST0.BSP.ip=GPIO
USB_HOST0.BSP.mode=Output
USB_HOST0.BSP.name=Drive_VBUS_FS
USB_HOST0.BSP.solution=PA9
USB_HOST_M7.USBH_DEBUG_LEVEL-MSC_FS=0
USB_HOST_M7.USBH_HandleTypeDef-MSC_FS=hUsbHostFS
USB_HOST_M7.USBH_MAX_NUM_ENDPOINTS-MSC_FS=2
USB_HOST_M7.USBH_MAX_NUM_INTERFACES-MSC_FS=2
USB_HOST_M7.VirtualModeFS=Msc
USB_OTG_FS.Sof_enable=ENABLE
USB_OTG_FS.VirtualMode=Host_Only
USB_OTG_FS.dma_enable=ENABLE
USB_OTG_FS.phy_itface=HCD_PHY_EMBEDDED
VP_CRC_VS_CRC.Mode=CRC_Activate
VP_DMA2D_VS_DMA2D.Mode=DMA2D_Activate
VP_FATFS_M7_VS_USB.Mode=USB
VP_FREERTOS_M7_VS_CMSIS_V2.Mode=CMSIS_V2
VP_RCC_LSE.Mode=CRS SYNC Source LSE
VP_RTC_VS_RTC_Activate.Mode=RTC_Enabled
VP_STMicroelectronics.X-CUBE-TOUCHGFX_M7_VS_GraphicsJjApplication_4.22.0.Mode=GraphicsJjApplication
VP_SYS_M4_VS_Systick.Mode=SysTick
VP_SYS_VS_tim6.Mode=TIM6
VP_TIM14_VS_ClockSourceINT.Mode=Enable_Timer
VP_TIM15_VS_ClockSourceINT.Mode=Internal
VP_TIM16_VS_ClockSourceINT.Mode=Enable_Timer
VP_TIM17_VS_ClockSourceINT.Mode=Enable_Timer
VP_TIM1_VS_ClockSourceINT.Mode=Internal
VP_TIM5_VS_ClockSourceINT.Mode=Internal
VP_TIM7_VS_ClockSourceINT.Mode=Enable_Timer
VP_USB_HOST_M7_VS_USB_HOST_MSC_FS.Mode=MSC_FS
board=custom

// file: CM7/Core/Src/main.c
/* USER CODE BEGIN Header */
/**
  ******************************************************************************
  * @file           : main.c
  * @brief          : Main program body
  ******************************************************************************
  * @attention
  *
  * <h2><center>&copy; Copyright (c) 2021 STMicroelectronics.
  * All rights reserved.</center></h2>
  *
  * This software component is licensed by ST under Ultimate Liberty license
  * SLA0044, the "License"; You may not use this file except in compliance with
  * the License. You may obtain a copy of the License at:
  *                             www.st.com/SLA0044
  *
  ******************************************************************************
  */
/* USER CODE END Header */
#include "main.h"
#include "cmsis_os.h"
#include "fatfs.h"
#include "app_touchgfx.h"

/* USER CODE BEGIN Includes */
#include "main_user.h"

/* USER CODE END Includes */

/* USER CODE BEGIN PD */

#ifndef HSEM_ID_0
#define HSEM_ID_0 (0U) /* HW semaphore 0*/
#endif
/* USER CODE END PD */

ADC_HandleTypeDef hadc1;
ADC_HandleTypeDef hadc2;
DMA_HandleTypeDef hdma_adc1;
DMA_HandleTypeDef hdma_adc2;

CRC_HandleTypeDef hcrc;

DMA2D_HandleTypeDef hdma2d;

LTDC_HandleTypeDef hltdc;

QSPI_HandleTypeDef hqspi;

RTC_HandleTypeDef hrtc;

SAI_HandleTypeDef hsai_BlockA2;
DMA_HandleTypeDef hdma_sai2_a;

MMC_HandleTypeDef hmmc1;

SPI_HandleTypeDef hspi2;
DMA_HandleTypeDef hdma_spi2_rx;
DMA_HandleTypeDef hdma_spi2_tx;

TIM_HandleTypeDef htim1;
TIM_HandleTypeDef htim5;
TIM_HandleTypeDef htim7;
TIM_HandleTypeDef htim14;
TIM_HandleTypeDef htim15;
TIM_HandleTypeDef htim16;
TIM_HandleTypeDef htim17;

UART_HandleTypeDef huart1;
UART_HandleTypeDef huart3;
DMA_HandleTypeDef hdma_usart1_rx;
DMA_HandleTypeDef hdma_usart1_tx;
DMA_HandleTypeDef hdma_usart3_rx;
DMA_HandleTypeDef hdma_usart3_tx;

MDMA_HandleTypeDef hmdma_mdma_channel10_sdmmc1_dma_endbuffer_0;
MDMA_LinkNodeTypeDef node_mdma_channel10_sdmmc1_command_end_1;
MDMA_LinkNodeTypeDef node_mdma_channel10_sdmmc1_end_data_2;
SDRAM_HandleTypeDef hsdram2;

/* Definitions for AppTask */
osThreadId_t AppTaskHandle;
const osThreadAttr_t AppTask_attributes = {
  .name = "AppTask",
  .stack_size = 1536 * 4,
  .priority = (osPriority_t) osPriorityNormal,
};
/* Definitions for TouchGFXTask */
osThreadId_t TouchGFXTaskHandle;
const osThreadAttr_t TouchGFXTask_attributes = {
  .name = "TouchGFXTask",
  .stack_size = 4096 * 4,
  .priority = (osPriority_t) osPriorityNormal,
};

void SystemClock_Config(void);
void PeriphCommonClock_Config(void);
static void MPU_Initialize(void);
static void MPU_Config(void);
static void MX_GPIO_Init(void);
static void MX_DMA_Init(void);
static void MX_MDMA_Init(void);
static void MX_FMC_Init(void);
static void MX_RTC_Init(void);
static void MX_LTDC_Init(void);
static void MX_QUADSPI_Init(void);
static void MX_DMA2D_Init(void);
static void MX_SDMMC1_MMC_Init(void);
static void MX_TIM1_Init(void);
static void MX_TIM5_Init(void);
static void MX_TIM7_Init(void);
static void MX_TIM14_Init(void);
static void MX_TIM15_Init(void);
static void MX_TIM16_Init(void);
static void MX_TIM17_Init(void);
static void MX_SAI2_Init(void);
static void MX_SPI2_Init(void);
static void MX_USART1_UART_Init(void);
static void MX_USART3_UART_Init(void);
static void MX_CRC_Init(void);
static void MX_ADC1_Init(void);
static void MX_ADC2_Init(void);
void App_Task(void *argument);
void TouchGFX_Task(void *argument);

int main(void)
{
/* USER CODE BEGIN Boot_Mode_Sequence_0 */
  int32_t timeout;
/* USER CODE END Boot_Mode_Sequence_0 */

  /* Enable I-Cache---------------------------------------------------------*/
  SCB_EnableICache();

/* USER CODE BEGIN Boot_Mode_Sequence_1 */
  /* Wait until CPU2 boots and enters in stop mode or timeout*/
  timeout = 0xFFFF;
  while((__HAL_RCC_GET_FLAG(RCC_FLAG_D2CKRDY) != RESET) && (timeout-- > 0));
  if ( timeout < 0 )
  {
  Error_Handler();
  }
/* USER CODE END Boot_Mode_Sequence_1 */
  /* MCU Configuration--------------------------------------------------------*/

  /* Reset of all peripherals, Initializes the Flash interface and the Systick. */
  HAL_Init();

  /* MPU Configuration--------------------------------------------------------*/
  MPU_Config();

  /* Configure the system clock */
  SystemClock_Config();

/* Configure the peripherals common clocks */
  PeriphCommonClock_Config();
/* USER CODE BEGIN Boot_Mode_Sequence_2 */
/* When system initialization is finished, Cortex-M7 will release Cortex-M4 by means of
HSEM notification */
/*HW semaphore Clock enable*/
__HAL_RCC_HSEM_CLK_ENABLE();
/*Take HSEM */
HAL_HSEM_FastTake(HSEM_ID_0);
/*Release HSEM in order to notify the CPU2(CM4)*/
HAL_HSEM_Release(HSEM_ID_0,0);
/* wait until CPU2 wakes up from stop mode */
timeout = 0xFFFF;
while((__HAL_RCC_GET_FLAG(RCC_FLAG_D2CKRDY) == RESET) && (timeout-- > 0));
if ( timeout < 0 )
{
Error_Handler();
}
/* USER CODE END Boot_Mode_Sequence_2 */

  /* USER CODE BEGIN SysInit */
  debug(2, "Initializing system...");
  /* USER CODE END SysInit */

  /* Initialize all configured peripherals */
  MX_GPIO_Init();
  MX_DMA_Init();
  MX_MDMA_Init();
  MX_FMC_Init();
  MX_RTC_Init();
  MX_LTDC_Init();
  MX_QUADSPI_Init();
  MX_DMA2D_Init();
  MX_SDMMC1_MMC_Init();
  MX_TIM1_Init();
  MX_TIM5_Init();
  MX_TIM7_Init();
  MX_TIM14_Init();
  MX_TIM15_Init();
  MX_TIM16_Init();
  MX_TIM17_Init();
  MX_SAI2_Init();
  MX_SPI2_Init();
  MX_USART1_UART_Init();
  MX_USART3_UART_Init();
  MX_FATFS_Init();
  MX_CRC_Init();
  MX_ADC1_Init();
  MX_ADC2_Init();
  MX_TouchGFX_Init();
  /* Call PreOsInit function */
  MX_TouchGFX_PreOSInit();
  /* USER CODE BEGIN 2 */
  debug_init(&DEBUG_PORT);
  debug(2, "System initialization completed.");
  /* USER CODE END 2 */

  /* Init scheduler */
  osKernelInitialize();

  /* Create the thread(s) */
  /* creation of AppTask */
  AppTaskHandle = osThreadNew(App_Task, NULL, &AppTask_attributes);

  /* creation of TouchGFXTask */
  TouchGFXTaskHandle = osThreadNew(TouchGFX_Task, NULL, &TouchGFXTask_attributes);

  /* USER CODE BEGIN RTOS_EVENTS */
  /* add events, ... */
  debug(2, "FreeRTOS kernel start...");
  /* USER CODE END RTOS_EVENTS */

  /* Start scheduler */
  osKernelStart();

  /* We should never get here as control is now taken by the scheduler */
  /* Infinite loop */
  while (1)
  {

  }
}

void SystemClock_Config(void)
{
  RCC_OscInitTypeDef RCC_OscInitStruct = {0};
  RCC_ClkInitTypeDef RCC_ClkInitStruct = {0};
  RCC_CRSInitTypeDef RCC_CRSInitStruct = {0};

  /** Supply configuration update enable
  */
  HAL_PWREx_ConfigSupply(PWR_DIRECT_SMPS_SUPPLY);

  /** Configure the main internal regulator output voltage
  */
  __HAL_PWR_VOLTAGESCALING_CONFIG(PWR_REGULATOR_VOLTAGE_SCALE1);

  while(!__HAL_PWR_GET_FLAG(PWR_FLAG_VOSRDY)) {}

  /** Configure LSE Drive Capability
  */
  HAL_PWR_EnableBkUpAccess();
  __HAL_RCC_LSEDRIVE_CONFIG(RCC_LSEDRIVE_LOW);

  /** Initializes the RCC Oscillators according to the specified parameters
  * in the RCC_OscInitTypeDef structure.
  */
  RCC_OscInitStruct.OscillatorType = RCC_OSCILLATORTYPE_HSI48|RCC_OSCILLATORTYPE_CSI
                              |RCC_OSCILLATORTYPE_HSE|RCC_OSCILLATORTYPE_LSE;
  RCC_OscInitStruct.HSEState = RCC_HSE_ON;
  RCC_OscInitStruct.LSEState = RCC_LSE_ON;
  RCC_OscInitStruct.HSI48State = RCC_HSI48_ON;
  RCC_OscInitStruct.CSIState = RCC_CSI_ON;
  RCC_OscInitStruct.CSICalibrationValue = RCC_CSICALIBRATION_DEFAULT;
  RCC_OscInitStruct.PLL.PLLState = RCC_PLL_ON;
  RCC_OscInitStruct.PLL.PLLSource = RCC_PLLSOURCE_HSE;
  RCC_OscInitStruct.PLL.PLLM = 5;
  RCC_OscInitStruct.PLL.PLLN = 160;
  RCC_OscInitStruct.PLL.PLLP = 2;
  RCC_OscInitStruct.PLL.PLLQ = 4;
  RCC_OscInitStruct.PLL.PLLR = 2;
  RCC_OscInitStruct.PLL.PLLRGE = RCC_PLL1VCIRANGE_2;
  RCC_OscInitStruct.PLL.PLLVCOSEL = RCC_PLL1VCOWIDE;
  RCC_OscInitStruct.PLL.PLLFRACN = 0;
  if (HAL_RCC_OscConfig(&RCC_OscInitStruct) != HAL_OK)
  {
    Error_Handler();
  }

  /** Initializes the CPU, AHB and APB buses clocks
  */
  RCC_ClkInitStruct.ClockType = RCC_CLOCKTYPE_HCLK|RCC_CLOCKTYPE_SYSCLK
                              |RCC_CLOCKTYPE_PCLK1|RCC_CLOCKTYPE_PCLK2
                              |RCC_CLOCKTYPE_D3PCLK1|RCC_CLOCKTYPE_D1PCLK1;
  RCC_ClkInitStruct.SYSCLKSource = RCC_SYSCLKSOURCE_PLLCLK;
  RCC_ClkInitStruct.SYSCLKDivider = RCC_SYSCLK_DIV1;
  RCC_ClkInitStruct.AHBCLKDivider = RCC_HCLK_DIV2;
  RCC_ClkInitStruct.APB3CLKDivider = RCC_APB3_DIV2;
  RCC_ClkInitStruct.APB1CLKDivider = RCC_APB1_DIV2;
  RCC_ClkInitStruct.APB2CLKDivider = RCC_APB2_DIV2;
  RCC_ClkInitStruct.APB4CLKDivider = RCC_APB4_DIV2;

  if (HAL_RCC_ClockConfig(&RCC_ClkInitStruct, FLASH_LATENCY_2) != HAL_OK)
  {
    Error_Handler();
  }

  /** Enable the SYSCFG APB clock
  */
  __HAL_RCC_CRS_CLK_ENABLE();

  /** Configures CRS
  */
  RCC_CRSInitStruct.Prescaler = RCC_CRS_SYNC_DIV1;
  RCC_CRSInitStruct.Source = RCC_CRS_SYNC_SOURCE_LSE;
  RCC_CRSInitStruct.Polarity = RCC_CRS_SYNC_POLARITY_RISING;
  RCC_CRSInitStruct.ReloadValue = __HAL_RCC_CRS_RELOADVALUE_CALCULATE(48000000,32768);
  RCC_CRSInitStruct.ErrorLimitValue = 34;
  RCC_CRSInitStruct.HSI48CalibrationValue = 32;

  HAL_RCCEx_CRSConfig(&RCC_CRSInitStruct);
}

void PeriphCommonClock_Config(void)
{
  RCC_PeriphCLKInitTypeDef PeriphClkInitStruct = {0};

  /** Initializes the peripherals clock
  */
  PeriphClkInitStruct.PeriphClockSelection = RCC_PERIPHCLK_SPI2|RCC_PERIPHCLK_CKPER
                              |RCC_PERIPHCLK_LTDC;
  PeriphClkInitStruct.PLL3.PLL3M = 5;
  PeriphClkInitStruct.PLL3.PLL3N = 160;
  PeriphClkInitStruct.PLL3.PLL3P = 20;
  PeriphClkInitStruct.PLL3.PLL3Q = 2;
  PeriphClkInitStruct.PLL3.PLL3R = 83;
  PeriphClkInitStruct.PLL3.PLL3RGE = RCC_PLL3VCIRANGE_2;
  PeriphClkInitStruct.PLL3.PLL3VCOSEL = RCC_PLL3VCOWIDE;
  PeriphClkInitStruct.PLL3.PLL3FRACN = 0;
  PeriphClkInitStruct.CkperClockSelection = RCC_CLKPSOURCE_CSI;
  PeriphClkInitStruct.Spi123ClockSelection = RCC_SPI123CLKSOURCE_PLL3;
  if (HAL_RCCEx_PeriphCLKConfig(&PeriphClkInitStruct) != HAL_OK)
  {
    Error_Handler();
  }
}

static void MX_ADC1_Init(void)
{

  ADC_MultiModeTypeDef multimode = {0};
  ADC_ChannelConfTypeDef sConfig = {0};

  /** Common config
  */
  hadc1.Instance = ADC1;
  hadc1.Init.ClockPrescaler = ADC_CLOCK_ASYNC_DIV4;
  hadc1.Init.Resolution = ADC_RESOLUTION_16B;
  hadc1.Init.ScanConvMode = ADC_SCAN_DISABLE;
  hadc1.Init.EOCSelection = ADC_EOC_SINGLE_CONV;
  hadc1.Init.LowPowerAutoWait = DISABLE;
  hadc1.Init.ContinuousConvMode = ENABLE;
  hadc1.Init.NbrOfConversion = 1;
  hadc1.Init.DiscontinuousConvMode = DISABLE;
  hadc1.Init.ExternalTrigConv = ADC_SOFTWARE_START;
  hadc1.Init.ExternalTrigConvEdge = ADC_EXTERNALTRIGCONVEDGE_NONE;
  hadc1.Init.ConversionDataManagement = ADC_CONVERSIONDATA_DMA_CIRCULAR;
  hadc1.Init.Overrun = ADC_OVR_DATA_PRESERVED;
  hadc1.Init.LeftBitShift = ADC_LEFTBITSHIFT_NONE;
  hadc1.Init.OversamplingMode = DISABLE;
  if (HAL_ADC_Init(&hadc1) != HAL_OK)
  {
    Error_Handler();
  }

  /** Configure the ADC multi-mode
  */
  multimode.Mode = ADC_MODE_INDEPENDENT;
  if (HAL_ADCEx_MultiModeConfigChannel(&hadc1, &multimode) != HAL_OK)
  {
    Error_Handler();
  }

  /** Configure Regular Channel
  */
  sConfig.Channel = ADC_CHANNEL_0;
  sConfig.Rank = ADC_REGULAR_RANK_1;
  sConfig.SamplingTime = ADC_SAMPLETIME_1CYCLE_5;
  sConfig.SingleDiff = ADC_SINGLE_ENDED;
  sConfig.OffsetNumber = ADC_OFFSET_NONE;
  sConfig.Offset = 0;
  sConfig.OffsetSignedSaturation = DISABLE;
  if (HAL_ADC_ConfigChannel(&hadc1, &sConfig) != HAL_OK)
  {
    Error_Handler();
  }

}

static void MX_ADC2_Init(void)
{

  ADC_ChannelConfTypeDef sConfig = {0};

  /** Common config
  */
  hadc2.Instance = ADC2;
  hadc2.Init.ClockPrescaler = ADC_CLOCK_ASYNC_DIV4;
  hadc2.Init.Resolution = ADC_RESOLUTION_16B;
  hadc2.Init.ScanConvMode = ADC_SCAN_DISABLE;
  hadc2.Init.EOCSelection = ADC_EOC_SINGLE_CONV;
  hadc2.Init.LowPowerAutoWait = DISABLE;
  hadc2.Init.ContinuousConvMode = ENABLE;
  hadc2.Init.NbrOfConversion = 1;
  hadc2.Init.DiscontinuousConvMode = DISABLE;
  hadc2.Init.ExternalTrigConv = ADC_SOFTWARE_START;
  hadc2.Init.ExternalTrigConvEdge = ADC_EXTERNALTRIGCONVEDGE_NONE;
  hadc2.Init.ConversionDataManagement = ADC_CONVERSIONDATA_DMA_CIRCULAR;
  hadc2.Init.Overrun = ADC_OVR_DATA_PRESERVED;
  hadc2.Init.LeftBitShift = ADC_LEFTBITSHIFT_NONE;
  hadc2.Init.OversamplingMode = DISABLE;
  if (HAL_ADC_Init(&hadc2) != HAL_OK)
  {
    Error_Handler();
  }

  /** Configure Regular Channel
  */
  sConfig.Channel = ADC_CHANNEL_1;
  sConfig.Rank = ADC_REGULAR_RANK_1;
  sConfig.SamplingTime = ADC_SAMPLETIME_1CYCLE_5;
  sConfig.SingleDiff = ADC_SINGLE_ENDED;
  sConfig.OffsetNumber = ADC_OFFSET_NONE;
  sConfig.Offset = 0;
  sConfig.OffsetSignedSaturation = DISABLE;
  if (HAL_ADC_ConfigChannel(&hadc2, &sConfig) != HAL_OK)
  {
    Error_Handler();
  }

}

static void MX_CRC_Init(void)
{

  hcrc.Instance = CRC;
  hcrc.Init.DefaultPolynomialUse = DEFAULT_POLYNOMIAL_ENABLE;
  hcrc.Init.DefaultInitValueUse = DEFAULT_INIT_VALUE_ENABLE;
  hcrc.Init.InputDataInversionMode = CRC_INPUTDATA_INVERSION_NONE;
  hcrc.Init.OutputDataInversionMode = CRC_OUTPUTDATA_INVERSION_DISABLE;
  hcrc.InputDataFormat = CRC_INPUTDATA_FORMAT_BYTES;
  if (HAL_CRC_Init(&hcrc) != HAL_OK)
  {
    Error_Handler();
  }

}

static void MX_DMA2D_Init(void)
{

  hdma2d.Instance = DMA2D;
  hdma2d.Init.Mode = DMA2D_R2M;
  hdma2d.Init.ColorMode = DMA2D_OUTPUT_RGB565;
  hdma2d.Init.OutputOffset = 0;
  if (HAL_DMA2D_Init(&hdma2d) != HAL_OK)
  {
    Error_Handler();
  }

}

static void MX_LTDC_Init(void)
{

  /* USER CODE BEGIN LTDC_Init 0 */
  initLtdcClocks();
  /* USER CODE END LTDC_Init 0 */

  LTDC_LayerCfgTypeDef pLayerCfg = {0};

  hltdc.Instance = LTDC;
  hltdc.Init.HSPolarity = LTDC_HSPOLARITY_AL;
  hltdc.Init.VSPolarity = LTDC_VSPOLARITY_AL;
  hltdc.Init.DEPolarity = LTDC_DEPOLARITY_AL;
  hltdc.Init.PCPolarity = LTDC_PCPOLARITY_IPC;
  hltdc.Init.HorizontalSync = 40;
  hltdc.Init.VerticalSync = 9;
  hltdc.Init.AccumulatedHBP = 53;
  hltdc.Init.AccumulatedVBP = 11;
  hltdc.Init.AccumulatedActiveW = 533;
  hltdc.Init.AccumulatedActiveH = 283;
  hltdc.Init.TotalWidth = 565;
  hltdc.Init.TotalHeigh = 285;
  hltdc.Init.Backcolor.Blue = 0;
  hltdc.Init.Backcolor.Green = 0;
  hltdc.Init.Backcolor.Red = 0;
  if (HAL_LTDC_Init(&hltdc) != HAL_OK)
  {
    Error_Handler();
  }
  pLayerCfg.WindowX0 = 0;
  pLayerCfg.WindowX1 = 480;
  pLayerCfg.WindowY0 = 0;
  pLayerCfg.WindowY1 = 272;
  pLayerCfg.PixelFormat = LTDC_PIXEL_FORMAT_RGB565;
  pLayerCfg.Alpha = 255;
  pLayerCfg.Alpha0 = 0;
  pLayerCfg.BlendingFactor1 = LTDC_BLENDING_FACTOR1_CA;
  pLayerCfg.BlendingFactor2 = LTDC_BLENDING_FACTOR2_CA;
  pLayerCfg.FBStartAdress = 0xD0000000;
  pLayerCfg.ImageWidth = 480;
  pLayerCfg.ImageHeight = 272;
  pLayerCfg.Backcolor.Blue = 0;
  pLayerCfg.Backcolor.Green = 0;
  pLayerCfg.Backcolor.Red = 0;
  if (HAL_LTDC_ConfigLayer(&hltdc, &pLayerCfg, 0) != HAL_OK)
  {
    Error_Handler();
  }

}

static void MX_QUADSPI_Init(void)
{

  /* QUADSPI parameter configuration*/
  hqspi.Instance = QUADSPI;
  hqspi.Init.ClockPrescaler = 1;
  hqspi.Init.FifoThreshold = 1;
  hqspi.Init.SampleShifting = QSPI_SAMPLE_SHIFTING_HALFCYCLE;
  hqspi.Init.FlashSize = 26;
  hqspi.Init.ChipSelectHighTime = QSPI_CS_HIGH_TIME_3_CYCLE;
  hqspi.Init.ClockMode = QSPI_CLOCK_MODE_0;
  hqspi.Init.DualFlash = QSPI_DUALFLASH_ENABLE;
  if (HAL_QSPI_Init(&hqspi) != HAL_OK)
  {
    Error_Handler();
  }
  /* USER CODE BEGIN QUADSPI_Init 2 */
  initBspQuadSpi(&Error_Handler);
  /* USER CODE END QUADSPI_Init 2 */

}

static void MX_RTC_Init(void)
{

  /* USER CODE BEGIN RTC_Init 0 */

  // THE WORKAROUND FOR A 1 SECOND LOSS ON RESTART STARTS HERE:

  // The Init structure initialization code is copied from the generated part, it can't be moved since the Cube can't be made to do so.
  hrtc.Instance = RTC;
  hrtc.Init.HourFormat = RTC_HOURFORMAT_24;
  hrtc.Init.AsynchPrediv = 127;
  hrtc.Init.SynchPrediv = 255;
  hrtc.Init.OutPut = RTC_OUTPUT_DISABLE;
  hrtc.Init.OutPutPolarity = RTC_OUTPUT_POLARITY_HIGH;
  hrtc.Init.OutPutType = RTC_OUTPUT_TYPE_OPENDRAIN;
  hrtc.Init.OutPutRemap = RTC_OUTPUT_REMAP_NONE;
  // The copied code ends here. The proper initialization ahead:
  uint32_t datetmpreg = (uint32_t)(hrtc.Instance->DR & RTC_DR_RESERVED_MASK); // DR is not zero even when not reset.
  uint8_t year = (uint8_t)((datetmpreg & (RTC_DR_YT | RTC_DR_YU)) >> RTC_DR_YU_Pos); // So we take the year from DR.
  if (year) // Over-simplified detection the clock has been set - year bits are not zero.
  { // The clock has been set, we skip broken initialization here to avoid resetting fraction of seconds bits.
    if (hrtc.State == HAL_RTC_STATE_RESET) hrtc.Lock = HAL_UNLOCKED;
    hrtc.State = HAL_RTC_STATE_BUSY;
    __HAL_RTC_WRITEPROTECTION_DISABLE(&hrtc);
    hrtc.Instance->CR &= ~(RTC_CR_FMT | RTC_CR_OSEL | RTC_CR_POL); // Clear RTC_CR FMT, OSEL and POL Bits.
    hrtc.Instance->CR |= (hrtc.Init.HourFormat | hrtc.Init.OutPut | hrtc.Init.OutPutPolarity); // Set RTC_CR register to avoid 12/24h time format random bug.
    hrtc.State = HAL_RTC_STATE_READY;
    __HAL_RTC_WRITEPROTECTION_ENABLE(&hrtc);
  }
  else
  { // Original initialization otherwise.
    if (HAL_RTC_Init(&hrtc) != HAL_OK)
    {
      Error_Handler();
    }
  }
  return;

  // THE WORKAROUND FOR A 1 SECOND LOSS ON RESTART ENDS HERE.

  /* USER CODE END RTC_Init 0 */

  /** Initialize RTC Only
  */
  hrtc.Instance = RTC;
  hrtc.Init.HourFormat = RTC_HOURFORMAT_24;
  hrtc.Init.AsynchPrediv = 127;
  hrtc.Init.SynchPrediv = 255;
  hrtc.Init.OutPut = RTC_OUTPUT_DISABLE;
  hrtc.Init.OutPutPolarity = RTC_OUTPUT_POLARITY_HIGH;
  hrtc.Init.OutPutType = RTC_OUTPUT_TYPE_OPENDRAIN;
  hrtc.Init.OutPutRemap = RTC_OUTPUT_REMAP_NONE;
  if (HAL_RTC_Init(&hrtc) != HAL_OK)
  {
    Error_Handler();
  }

}

static void MX_SAI2_Init(void)
{

  hsai_BlockA2.Instance = SAI2_Block_A;
  hsai_BlockA2.Init.Protocol = SAI_FREE_PROTOCOL;
  hsai_BlockA2.Init.AudioMode = SAI_MODEMASTER_TX;
  hsai_BlockA2.Init.DataSize = SAI_DATASIZE_16;
  hsai_BlockA2.Init.FirstBit = SAI_FIRSTBIT_MSB;
  hsai_BlockA2.Init.ClockStrobing = SAI_CLOCKSTROBING_RISINGEDGE;
  hsai_BlockA2.Init.Synchro = SAI_ASYNCHRONOUS;
  hsai_BlockA2.Init.OutputDrive = SAI_OUTPUTDRIVE_ENABLE;
  hsai_BlockA2.Init.NoDivider = SAI_MASTERDIVIDER_ENABLE;
  hsai_BlockA2.Init.FIFOThreshold = SAI_FIFOTHRESHOLD_EMPTY;
  hsai_BlockA2.Init.AudioFrequency = SAI_AUDIO_FREQUENCY_22K;
  hsai_BlockA2.Init.SynchroExt = SAI_SYNCEXT_DISABLE;
  hsai_BlockA2.Init.MonoStereoMode = SAI_STEREOMODE;
  hsai_BlockA2.Init.CompandingMode = SAI_NOCOMPANDING;
  hsai_BlockA2.Init.TriState = SAI_OUTPUT_NOTRELEASED;
  hsai_BlockA2.Init.PdmInit.Activation = DISABLE;
  hsai_BlockA2.Init.PdmInit.MicPairsNbr = 1;
  hsai_BlockA2.Init.PdmInit.ClockEnable = SAI_PDM_CLOCK1_ENABLE;
  hsai_BlockA2.FrameInit.FrameLength = 128;
  hsai_BlockA2.FrameInit.ActiveFrameLength = 64;
  hsai_BlockA2.FrameInit.FSDefinition = SAI_FS_CHANNEL_IDENTIFICATION;
  hsai_BlockA2.FrameInit.FSPolarity = SAI_FS_ACTIVE_LOW;
  hsai_BlockA2.FrameInit.FSOffset = SAI_FS_BEFOREFIRSTBIT;
  hsai_BlockA2.SlotInit.FirstBitOffset = 0;
  hsai_BlockA2.SlotInit.SlotSize = SAI_SLOTSIZE_DATASIZE;
  hsai_BlockA2.SlotInit.SlotNumber = 2;
  hsai_BlockA2.SlotInit.SlotActive = 0x0000FFFF;
  if (HAL_SAI_Init(&hsai_BlockA2) != HAL_OK)
  {
    Error_Handler();
  }

}

static void MX_SDMMC1_MMC_Init(void)
{

  hmmc1.Instance = SDMMC1;
  hmmc1.Init.ClockEdge = SDMMC_CLOCK_EDGE_RISING;
  hmmc1.Init.ClockPowerSave = SDMMC_CLOCK_POWER_SAVE_DISABLE;
  hmmc1.Init.BusWide = SDMMC_BUS_WIDE_8B;
  hmmc1.Init.HardwareFlowControl = SDMMC_HARDWARE_FLOW_CONTROL_ENABLE;
  hmmc1.Init.ClockDiv = 2;
  if (HAL_MMC_Init(&hmmc1) != HAL_OK)
  {
    Error_Handler();
  }

}

static void MX_SPI2_Init(void)
{

  /* SPI2 parameter configuration*/
  hspi2.Instance = SPI2;
  hspi2.Init.Mode = SPI_MODE_MASTER;
  hspi2.Init.Direction = SPI_DIRECTION_2LINES;
  hspi2.Init.DataSize = SPI_DATASIZE_8BIT;
  hspi2.Init.CLKPolarity = SPI_POLARITY_LOW;
  hspi2.Init.CLKPhase = SPI_PHASE_1EDGE;
  hspi2.Init.NSS = SPI_NSS_SOFT;
  hspi2.Init.BaudRatePrescaler = SPI_BAUDRATEPRESCALER_8;
  hspi2.Init.FirstBit = SPI_FIRSTBIT_MSB;
  hspi2.Init.TIMode = SPI_TIMODE_DISABLE;
  hspi2.Init.CRCCalculation = SPI_CRCCALCULATION_DISABLE;
  hspi2.Init.CRCPolynomial = 0x0;
  hspi2.Init.NSSPMode = SPI_NSS_PULSE_DISABLE;
  hspi2.Init.NSSPolarity = SPI_NSS_POLARITY_LOW;
  hspi2.Init.FifoThreshold = SPI_FIFO_THRESHOLD_01DATA;
  hspi2.Init.TxCRCInitializationPattern = SPI_CRC_INITIALIZATION_ALL_ZERO_PATTERN;
  hspi2.Init.RxCRCInitializationPattern = SPI_CRC_INITIALIZATION_ALL_ZERO_PATTERN;
  hspi2.Init.MasterSSIdleness = SPI_MASTER_SS_IDLENESS_00CYCLE;
  hspi2.Init.MasterInterDataIdleness = SPI_MASTER_INTERDATA_IDLENESS_00CYCLE;
  hspi2.Init.MasterReceiverAutoSusp = SPI_MASTER_RX_AUTOSUSP_DISABLE;
  hspi2.Init.MasterKeepIOState = SPI_MASTER_KEEP_IO_STATE_ENABLE;
  hspi2.Init.IOSwap = SPI_IO_SWAP_DISABLE;
  if (HAL_SPI_Init(&hspi2) != HAL_OK)
  {
    Error_Handler();
  }

}

static void MX_TIM1_Init(void)
{

  TIM_ClockConfigTypeDef sClockSourceConfig = {0};
  TIM_MasterConfigTypeDef sMasterConfig = {0};
  TIM_OC_InitTypeDef sConfigOC = {0};
  TIM_BreakDeadTimeConfigTypeDef sBreakDeadTimeConfig = {0};

  htim1.Instance = TIM1;
  htim1.Init.Prescaler = 2-1;
  htim1.Init.CounterMode = TIM_COUNTERMODE_UP;
  htim1.Init.Period = 1000-1;
  htim1.Init.ClockDivision = TIM_CLOCKDIVISION_DIV1;
  htim1.Init.RepetitionCounter = 0;
  htim1.Init.AutoReloadPreload = TIM_AUTORELOAD_PRELOAD_DISABLE;
  if (HAL_TIM_Base_Init(&htim1) != HAL_OK)
  {
    Error_Handler();
  }
  sClockSourceConfig.ClockSource = TIM_CLOCKSOURCE_INTERNAL;
  if (HAL_TIM_ConfigClockSource(&htim1, &sClockSourceConfig) != HAL_OK)
  {
    Error_Handler();
  }
  if (HAL_TIM_PWM_Init(&htim1) != HAL_OK)
  {
    Error_Handler();
  }
  sMasterConfig.MasterOutputTrigger = TIM_TRGO_RESET;
  sMasterConfig.MasterOutputTrigger2 = TIM_TRGO2_RESET;
  sMasterConfig.MasterSlaveMode = TIM_MASTERSLAVEMODE_DISABLE;
  if (HAL_TIMEx_MasterConfigSynchronization(&htim1, &sMasterConfig) != HAL_OK)
  {
    Error_Handler();
  }
  sConfigOC.OCMode = TIM_OCMODE_PWM1;
  sConfigOC.Pulse = 0;
  sConfigOC.OCPolarity = TIM_OCPOLARITY_HIGH;
  sConfigOC.OCNPolarity = TIM_OCNPOLARITY_HIGH;
  sConfigOC.OCFastMode = TIM_OCFAST_DISABLE;
  sConfigOC.OCIdleState = TIM_OCIDLESTATE_RESET;
  sConfigOC.OCNIdleState = TIM_OCNIDLESTATE_RESET;
  if (HAL_TIM_PWM_ConfigChannel(&htim1, &sConfigOC, TIM_CHANNEL_1) != HAL_OK)
  {
    Error_Handler();
  }
  sBreakDeadTimeConfig.OffStateRunMode = TIM_OSSR_DISABLE;
  sBreakDeadTimeConfig.OffStateIDLEMode = TIM_OSSI_DISABLE;
  sBreakDeadTimeConfig.LockLevel = TIM_LOCKLEVEL_OFF;
  sBreakDeadTimeConfig.DeadTime = 0;
  sBreakDeadTimeConfig.BreakState = TIM_BREAK_DISABLE;
  sBreakDeadTimeConfig.BreakPolarity = TIM_BREAKPOLARITY_HIGH;
  sBreakDeadTimeConfig.BreakFilter = 0;
  sBreakDeadTimeConfig.Break2State = TIM_BREAK2_DISABLE;
  sBreakDeadTimeConfig.Break2Polarity = TIM_BREAK2POLARITY_HIGH;
  sBreakDeadTimeConfig.Break2Filter = 0;
  sBreakDeadTimeConfig.AutomaticOutput = TIM_AUTOMATICOUTPUT_DISABLE;
  if (HAL_TIMEx_ConfigBreakDeadTime(&htim1, &sBreakDeadTimeConfig) != HAL_OK)
  {
    Error_Handler();
  }
  HAL_TIM_MspPostInit(&htim1);

}

static void MX_TIM5_Init(void)
{

  TIM_ClockConfigTypeDef sClockSourceConfig = {0};
  TIM_MasterConfigTypeDef sMasterConfig = {0};

  htim5.Instance = TIM5;
  htim5.Init.Prescaler = 2000-1;
  htim5.Init.CounterMode = TIM_COUNTERMODE_UP;
  htim5.Init.Period = 4294967295;
  htim5.Init.ClockDivision = TIM_CLOCKDIVISION_DIV1;
  htim5.Init.AutoReloadPreload = TIM_AUTORELOAD_PRELOAD_DISABLE;
  if (HAL_TIM_Base_Init(&htim5) != HAL_OK)
  {
    Error_Handler();
  }
  sClockSourceConfig.ClockSource = TIM_CLOCKSOURCE_INTERNAL;
  if (HAL_TIM_ConfigClockSource(&htim5, &sClockSourceConfig) != HAL_OK)
  {
    Error_Handler();
  }
  sMasterConfig.MasterOutputTrigger = TIM_TRGO_RESET;
  sMasterConfig.MasterSlaveMode = TIM_MASTERSLAVEMODE_DISABLE;
  if (HAL_TIMEx_MasterConfigSynchronization(&htim5, &sMasterConfig) != HAL_OK)
  {
    Error_Handler();
  }

}

static void MX_TIM7_Init(void)
{

  TIM_MasterConfigTypeDef sMasterConfig = {0};

  htim7.Instance = TIM7;
  htim7.Init.Prescaler = 2-1;
  htim7.Init.CounterMode = TIM_COUNTERMODE_UP;
  htim7.Init.Period = 65535;
  htim7.Init.AutoReloadPreload = TIM_AUTORELOAD_PRELOAD_DISABLE;
  if (HAL_TIM_Base_Init(&htim7) != HAL_OK)
  {
    Error_Handler();
  }
  sMasterConfig.MasterOutputTrigger = TIM_TRGO_RESET;
  sMasterConfig.MasterSlaveMode = TIM_MASTERSLAVEMODE_DISABLE;
  if (HAL_TIMEx_MasterConfigSynchronization(&htim7, &sMasterConfig) != HAL_OK)
  {
    Error_Handler();
  }

}

static void MX_TIM14_Init(void)
{

  htim14.Instance = TIM14;
  htim14.Init.Prescaler = 200-1;
  htim14.Init.CounterMode = TIM_COUNTERMODE_UP;
  htim14.Init.Period = 1000-1;
  htim14.Init.ClockDivision = TIM_CLOCKDIVISION_DIV1;
  htim14.Init.AutoReloadPreload = TIM_AUTORELOAD_PRELOAD_DISABLE;
  if (HAL_TIM_Base_Init(&htim14) != HAL_OK)
  {
    Error_Handler();
  }

}

static void MX_TIM15_Init(void)
{

  TIM_ClockConfigTypeDef sClockSourceConfig = {0};
  TIM_MasterConfigTypeDef sMasterConfig = {0};
  TIM_OC_InitTypeDef sConfigOC = {0};
  TIM_BreakDeadTimeConfigTypeDef sBreakDeadTimeConfig = {0};

  htim15.Instance = TIM15;
  htim15.Init.Prescaler = 2-1;
  htim15.Init.CounterMode = TIM_COUNTERMODE_UP;
  htim15.Init.Period = 1000-1;
  htim15.Init.ClockDivision = TIM_CLOCKDIVISION_DIV1;
  htim15.Init.RepetitionCounter = 0;
  htim15.Init.AutoReloadPreload = TIM_AUTORELOAD_PRELOAD_DISABLE;
  if (HAL_TIM_Base_Init(&htim15) != HAL_OK)
  {
    Error_Handler();
  }
  sClockSourceConfig.ClockSource = TIM_CLOCKSOURCE_INTERNAL;
  if (HAL_TIM_ConfigClockSource(&htim15, &sClockSourceConfig) != HAL_OK)
  {
    Error_Handler();
  }
  if (HAL_TIM_PWM_Init(&htim15) != HAL_OK)
  {
    Error_Handler();
  }
  sMasterConfig.MasterOutputTrigger = TIM_TRGO_RESET;
  sMasterConfig.MasterSlaveMode = TIM_MASTERSLAVEMODE_DISABLE;
  if (HAL_TIMEx_MasterConfigSynchronization(&htim15, &sMasterConfig) != HAL_OK)
  {
    Error_Handler();
  }
  sConfigOC.OCMode = TIM_OCMODE_PWM1;
  sConfigOC.Pulse = 0;
  sConfigOC.OCPolarity = TIM_OCPOLARITY_HIGH;
  sConfigOC.OCNPolarity = TIM_OCNPOLARITY_HIGH;
  sConfigOC.OCFastMode = TIM_OCFAST_DISABLE;
  sConfigOC.OCIdleState = TIM_OCIDLESTATE_RESET;
  sConfigOC.OCNIdleState = TIM_OCNIDLESTATE_RESET;
  if (HAL_TIM_PWM_ConfigChannel(&htim15, &sConfigOC, TIM_CHANNEL_2) != HAL_OK)
  {
    Error_Handler();
  }
  sBreakDeadTimeConfig.OffStateRunMode = TIM_OSSR_DISABLE;
  sBreakDeadTimeConfig.OffStateIDLEMode = TIM_OSSI_DISABLE;
  sBreakDeadTimeConfig.LockLevel = TIM_LOCKLEVEL_OFF;
  sBreakDeadTimeConfig.DeadTime = 0;
  sBreakDeadTimeConfig.BreakState = TIM_BREAK_DISABLE;
  sBreakDeadTimeConfig.BreakPolarity = TIM_BREAKPOLARITY_HIGH;
  sBreakDeadTimeConfig.BreakFilter = 0;
  sBreakDeadTimeConfig.AutomaticOutput = TIM_AUTOMATICOUTPUT_DISABLE;
  if (HAL_TIMEx_ConfigBreakDeadTime(&htim15, &sBreakDeadTimeConfig) != HAL_OK)
  {
    Error_Handler();
  }
  HAL_TIM_MspPostInit(&htim15);

}

static void MX_TIM16_Init(void)
{

  htim16.Instance = TIM16;
  htim16.Init.Prescaler = 0;
  htim16.Init.CounterMode = TIM_COUNTERMODE_UP;
  htim16.Init.Period = 65535;
  htim16.Init.ClockDivision = TIM_CLOCKDIVISION_DIV1;
  htim16.Init.RepetitionCounter = 0;
  htim16.Init.AutoReloadPreload = TIM_AUTORELOAD_PRELOAD_DISABLE;
  if (HAL_TIM_Base_Init(&htim16) != HAL_OK)
  {
    Error_Handler();
  }

}

static void MX_TIM17_Init(void)
{

  htim17.Instance = TIM17;
  htim17.Init.Prescaler = 200-1;
  htim17.Init.CounterMode = TIM_COUNTERMODE_UP;
  htim17.Init.Period = 1000-1;
  htim17.Init.ClockDivision = TIM_CLOCKDIVISION_DIV1;
  htim17.Init.RepetitionCounter = 0;
  htim17.Init.AutoReloadPreload = TIM_AUTORELOAD_PRELOAD_DISABLE;
  if (HAL_TIM_Base_Init(&htim17) != HAL_OK)
  {
    Error_Handler();
  }

}

static void MX_USART1_UART_Init(void)
{

  huart1.Instance = USART1;
  huart1.Init.BaudRate = 9600;
  huart1.Init.WordLength = UART_WORDLENGTH_8B;
  huart1.Init.StopBits = UART_STOPBITS_1;
  huart1.Init.Parity = UART_PARITY_NONE;
  huart1.Init.Mode = UART_MODE_TX_RX;
  huart1.Init.HwFlowCtl = UART_HWCONTROL_NONE;
  huart1.Init.OverSampling = UART_OVERSAMPLING_16;
  huart1.Init.OneBitSampling = UART_ONE_BIT_SAMPLE_DISABLE;
  huart1.Init.ClockPrescaler = UART_PRESCALER_DIV1;
  huart1.AdvancedInit.AdvFeatureInit = UART_ADVFEATURE_NO_INIT;
  if (HAL_UART_Init(&huart1) != HAL_OK)
  {
    Error_Handler();
  }
  if (HAL_UARTEx_SetTxFifoThreshold(&huart1, UART_TXFIFO_THRESHOLD_1_8) != HAL_OK)
  {
    Error_Handler();
  }
  if (HAL_UARTEx_SetRxFifoThreshold(&huart1, UART_RXFIFO_THRESHOLD_1_8) != HAL_OK)
  {
    Error_Handler();
  }
  if (HAL_UARTEx_DisableFifoMode(&huart1) != HAL_OK)
  {
    Error_Handler();
  }

}

static void MX_USART3_UART_Init(void)
{

  huart3.Instance = USART3;
  huart3.Init.BaudRate = 115200;
  huart3.Init.WordLength = UART_WORDLENGTH_8B;
  huart3.Init.StopBits = UART_STOPBITS_1;
  huart3.Init.Parity = UART_PARITY_NONE;
  huart3.Init.Mode = UART_MODE_TX_RX;
  huart3.Init.HwFlowCtl = UART_HWCONTROL_NONE;
  huart3.Init.OverSampling = UART_OVERSAMPLING_16;
  huart3.Init.OneBitSampling = UART_ONE_BIT_SAMPLE_DISABLE;
  huart3.Init.ClockPrescaler = UART_PRESCALER_DIV1;
  huart3.AdvancedInit.AdvFeatureInit = UART_ADVFEATURE_NO_INIT;
  if (HAL_RS485Ex_Init(&huart3, UART_DE_POLARITY_HIGH, 0, 0) != HAL_OK)
  {
    Error_Handler();
  }
  if (HAL_UARTEx_SetTxFifoThreshold(&huart3, UART_TXFIFO_THRESHOLD_1_8) != HAL_OK)
  {
    Error_Handler();
  }
  if (HAL_UARTEx_SetRxFifoThreshold(&huart3, UART_RXFIFO_THRESHOLD_1_8) != HAL_OK)
  {
    Error_Handler();
  }
  if (HAL_UARTEx_DisableFifoMode(&huart3) != HAL_OK)
  {
    Error_Handler();
  }

}

static void MX_DMA_Init(void)
{

  /* DMA controller clock enable */
  __HAL_RCC_DMA1_CLK_ENABLE();
  __HAL_RCC_DMA2_CLK_ENABLE();

  /* DMA interrupt init */
  /* DMA1_Stream0_IRQn interrupt configuration */
  HAL_NVIC_SetPriority(DMA1_Stream0_IRQn, 5, 0);
  HAL_NVIC_EnableIRQ(DMA1_Stream0_IRQn);
  /* DMA1_Stream1_IRQn interrupt configuration */
  HAL_NVIC_SetPriority(DMA1_Stream1_IRQn, 5, 0);
  HAL_NVIC_EnableIRQ(DMA1_Stream1_IRQn);
  /* DMA1_Stream2_IRQn interrupt configuration */
  HAL_NVIC_SetPriority(DMA1_Stream2_IRQn, 5, 0);
  HAL_NVIC_EnableIRQ(DMA1_Stream2_IRQn);
  /* DMA1_Stream3_IRQn interrupt configuration */
  HAL_NVIC_SetPriority(DMA1_Stream3_IRQn, 5, 0);
  HAL_NVIC_EnableIRQ(DMA1_Stream3_IRQn);
  /* DMA1_Stream4_IRQn interrupt configuration */
  HAL_NVIC_SetPriority(DMA1_Stream4_IRQn, 5, 0);
  HAL_NVIC_EnableIRQ(DMA1_Stream4_IRQn);
  /* DMA1_Stream5_IRQn interrupt configuration */
  HAL_NVIC_SetPriority(DMA1_Stream5_IRQn, 5, 0);
  HAL_NVIC_EnableIRQ(DMA1_Stream5_IRQn);
  /* DMA1_Stream6_IRQn interrupt configuration */
  HAL_NVIC_SetPriority(DMA1_Stream6_IRQn, 5, 0);
  HAL_NVIC_EnableIRQ(DMA1_Stream6_IRQn);
  /* DMA1_Stream7_IRQn interrupt configuration */
  HAL_NVIC_SetPriority(DMA1_Stream7_IRQn, 5, 0);
  HAL_NVIC_EnableIRQ(DMA1_Stream7_IRQn);
  /* DMA2_Stream1_IRQn interrupt configuration */
  HAL_NVIC_SetPriority(DMA2_Stream1_IRQn, 4, 0);
  HAL_NVIC_EnableIRQ(DMA2_Stream1_IRQn);

}

/**
  * Enable MDMA controller clock
  * Configure MDMA for global transfers
  *   hmdma_mdma_channel10_sdmmc1_dma_endbuffer_0
  *   node_mdma_channel10_sdmmc1_command_end_1
  *   node_mdma_channel10_sdmmc1_end_data_2
  */
static void MX_MDMA_Init(void)
{

  /* MDMA controller clock enable */
  __HAL_RCC_MDMA_CLK_ENABLE();
  /* Local variables */
  MDMA_LinkNodeConfTypeDef nodeConfig;

  /* Configure MDMA channel MDMA_Channel10 */
  /* Configure MDMA request hmdma_mdma_channel10_sdmmc1_dma_endbuffer_0 on MDMA_Channel10 */
  hmdma_mdma_channel10_sdmmc1_dma_endbuffer_0.Instance = MDMA_Channel10;
  hmdma_mdma_channel10_sdmmc1_dma_endbuffer_0.Init.Request = MDMA_REQUEST_SDMMC1_DMA_ENDBUFFER;
  hmdma_mdma_channel10_sdmmc1_dma_endbuffer_0.Init.TransferTriggerMode = MDMA_BLOCK_TRANSFER;
  hmdma_mdma_channel10_sdmmc1_dma_endbuffer_0.Init.Priority = MDMA_PRIORITY_MEDIUM;
  hmdma_mdma_channel10_sdmmc1_dma_endbuffer_0.Init.Endianness = MDMA_LITTLE_ENDIANNESS_PRESERVE;
  hmdma_mdma_channel10_sdmmc1_dma_endbuffer_0.Init.SourceInc = MDMA_SRC_INC_BYTE;
  hmdma_mdma_channel10_sdmmc1_dma_endbuffer_0.Init.DestinationInc = MDMA_DEST_INC_BYTE;
  hmdma_mdma_channel10_sdmmc1_dma_endbuffer_0.Init.SourceDataSize = MDMA_SRC_DATASIZE_BYTE;
  hmdma_mdma_channel10_sdmmc1_dma_endbuffer_0.Init.DestDataSize = MDMA_DEST_DATASIZE_BYTE;
  hmdma_mdma_channel10_sdmmc1_dma_endbuffer_0.Init.DataAlignment = MDMA_DATAALIGN_PACKENABLE;
  hmdma_mdma_channel10_sdmmc1_dma_endbuffer_0.Init.BufferTransferLength = 1;
  hmdma_mdma_channel10_sdmmc1_dma_endbuffer_0.Init.SourceBurst = MDMA_SOURCE_BURST_SINGLE;
  hmdma_mdma_channel10_sdmmc1_dma_endbuffer_0.Init.DestBurst = MDMA_DEST_BURST_SINGLE;
  hmdma_mdma_channel10_sdmmc1_dma_endbuffer_0.Init.SourceBlockAddressOffset = 0;
  hmdma_mdma_channel10_sdmmc1_dma_endbuffer_0.Init.DestBlockAddressOffset = 0;
  if (HAL_MDMA_Init(&hmdma_mdma_channel10_sdmmc1_dma_endbuffer_0) != HAL_OK)
  {
    Error_Handler();
  }

  /* Configure post request address and data masks */
  if (HAL_MDMA_ConfigPostRequestMask(&hmdma_mdma_channel10_sdmmc1_dma_endbuffer_0, 0, 0) != HAL_OK)
  {
    Error_Handler();
  }

  /* Initialize MDMA link node according to specified parameters */
  nodeConfig.Init.Request = MDMA_REQUEST_SDMMC1_COMMAND_END;
  nodeConfig.Init.TransferTriggerMode = MDMA_BLOCK_TRANSFER;
  nodeConfig.Init.Priority = MDMA_PRIORITY_MEDIUM;
  nodeConfig.Init.Endianness = MDMA_LITTLE_ENDIANNESS_PRESERVE;
  nodeConfig.Init.SourceInc = MDMA_SRC_INC_BYTE;
  nodeConfig.Init.DestinationInc = MDMA_DEST_INC_BYTE;
  nodeConfig.Init.SourceDataSize = MDMA_SRC_DATASIZE_BYTE;
  nodeConfig.Init.DestDataSize = MDMA_DEST_DATASIZE_BYTE;
  nodeConfig.Init.DataAlignment = MDMA_DATAALIGN_PACKENABLE;
  nodeConfig.Init.BufferTransferLength = 1;
  nodeConfig.Init.SourceBurst = MDMA_SOURCE_BURST_SINGLE;
  nodeConfig.Init.DestBurst = MDMA_DEST_BURST_SINGLE;
  nodeConfig.Init.SourceBlockAddressOffset = 0;
  nodeConfig.Init.DestBlockAddressOffset = 0;
  nodeConfig.PostRequestMaskAddress = 0;
  nodeConfig.PostRequestMaskData = 0;
  nodeConfig.SrcAddress = 0;
  nodeConfig.DstAddress = 0;
  nodeConfig.BlockDataLength = 0;
  nodeConfig.BlockCount = 0;
  if (HAL_MDMA_LinkedList_CreateNode(&node_mdma_channel10_sdmmc1_command_end_1, &nodeConfig) != HAL_OK)
  {
    Error_Handler();
  }

  /* Connect a node to the linked list */
  if (HAL_MDMA_LinkedList_AddNode(&hmdma_mdma_channel10_sdmmc1_dma_endbuffer_0, &node_mdma_channel10_sdmmc1_command_end_1, 0) != HAL_OK)
  {
    Error_Handler();
  }

  /* Initialize MDMA link node according to specified parameters */
  nodeConfig.Init.Request = MDMA_REQUEST_SDMMC1_END_DATA;
  nodeConfig.Init.TransferTriggerMode = MDMA_BLOCK_TRANSFER;
  nodeConfig.Init.Priority = MDMA_PRIORITY_MEDIUM;
  nodeConfig.Init.Endianness = MDMA_LITTLE_ENDIANNESS_PRESERVE;
  nodeConfig.Init.SourceInc = MDMA_SRC_INC_BYTE;
  nodeConfig.Init.DestinationInc = MDMA_DEST_INC_BYTE;
  nodeConfig.Init.SourceDataSize = MDMA_SRC_DATASIZE_BYTE;
  nodeConfig.Init.DestDataSize = MDMA_DEST_DATASIZE_BYTE;
  nodeConfig.Init.DataAlignment = MDMA_DATAALIGN_PACKENABLE;
  nodeConfig.Init.BufferTransferLength = 1;
  nodeConfig.Init.SourceBurst = MDMA_SOURCE_BURST_SINGLE;
  nodeConfig.Init.DestBurst = MDMA_DEST_BURST_SINGLE;
  nodeConfig.Init.SourceBlockAddressOffset = 0;
  nodeConfig.Init.DestBlockAddressOffset = 0;
  nodeConfig.PostRequestMaskAddress = 0;
  nodeConfig.PostRequestMaskData = 0;
  nodeConfig.SrcAddress = 0;
  nodeConfig.DstAddress = 0;
  nodeConfig.BlockDataLength = 0;
  nodeConfig.BlockCount = 0;
  if (HAL_MDMA_LinkedList_CreateNode(&node_mdma_channel10_sdmmc1_end_data_2, &nodeConfig) != HAL_OK)
  {
    Error_Handler();
  }

  /* Connect a node to the linked list */
  if (HAL_MDMA_LinkedList_AddNode(&hmdma_mdma_channel10_sdmmc1_dma_endbuffer_0, &node_mdma_channel10_sdmmc1_end_data_2, 0) != HAL_OK)
  {
    Error_Handler();
  }

  /* MDMA interrupt initialization */
  /* MDMA_IRQn interrupt configuration */
  HAL_NVIC_SetPriority(MDMA_IRQn, 1, 0);
  HAL_NVIC_EnableIRQ(MDMA_IRQn);

}

/* FMC initialization function */
void MX_FMC_Init(void)
{

  FMC_SDRAM_TimingTypeDef SdramTiming = {0};

  /** Perform the SDRAM2 memory initialization sequence
  */
  hsdram2.Instance = FMC_SDRAM_DEVICE;
  /* hsdram2.Init */
  hsdram2.Init.SDBank = FMC_SDRAM_BANK2;
  hsdram2.Init.ColumnBitsNumber = FMC_SDRAM_COLUMN_BITS_NUM_8;
  hsdram2.Init.RowBitsNumber = FMC_SDRAM_ROW_BITS_NUM_12;
  hsdram2.Init.MemoryDataWidth = FMC_SDRAM_MEM_BUS_WIDTH_16;
  hsdram2.Init.InternalBankNumber = FMC_SDRAM_INTERN_BANKS_NUM_4;
  hsdram2.Init.CASLatency = FMC_SDRAM_CAS_LATENCY_2;
  hsdram2.Init.WriteProtection = FMC_SDRAM_WRITE_PROTECTION_DISABLE;
  hsdram2.Init.SDClockPeriod = FMC_SDRAM_CLOCK_PERIOD_2;
  hsdram2.Init.ReadBurst = FMC_SDRAM_RBURST_ENABLE;
  hsdram2.Init.ReadPipeDelay = FMC_SDRAM_RPIPE_DELAY_0;
  /* SdramTiming */
  SdramTiming.LoadToActiveDelay = 2;
  SdramTiming.ExitSelfRefreshDelay = 6;
  SdramTiming.SelfRefreshTime = 4;
  SdramTiming.RowCycleDelay = 6;
  SdramTiming.WriteRecoveryTime = 2;
  SdramTiming.RPDelay = 2;
  SdramTiming.RCDDelay = 2;

  if (HAL_SDRAM_Init(&hsdram2, &SdramTiming) != HAL_OK)
  {
    Error_Handler( );
  }

  /* USER CODE BEGIN FMC_Init 2 */
  initBspSdRam(&Error_Handler);
  clearLTDCRam();

  /* USER CODE END FMC_Init 2 */
}

static void MX_GPIO_Init(void)
{
  GPIO_InitTypeDef GPIO_InitStruct = {0};

  /* GPIO Ports Clock Enable */
  __HAL_RCC_GPIOI_CLK_ENABLE();
  __HAL_RCC_GPIOK_CLK_ENABLE();
  __HAL_RCC_GPIOG_CLK_ENABLE();
  __HAL_RCC_GPIOC_CLK_ENABLE();
  __HAL_RCC_GPIOE_CLK_ENABLE();
  __HAL_RCC_GPIOB_CLK_ENABLE();
  __HAL_RCC_GPIOJ_CLK_ENABLE();
  __HAL_RCC_GPIOD_CLK_ENABLE();
  __HAL_RCC_GPIOA_CLK_ENABLE();
  __HAL_RCC_GPIOF_CLK_ENABLE();
  __HAL_RCC_GPIOH_CLK_ENABLE();

  /*Configure GPIO pin Output Level */
  HAL_GPIO_WritePin(GPIOA, VBUS_OTG_FS_Pin|OTG_FS2_PSO_Pin, GPIO_PIN_SET);

  /*Configure GPIO pin Output Level */
  HAL_GPIO_WritePin(SPI_CS_GPIO_Port, SPI_CS_Pin, GPIO_PIN_RESET);

  /*Configure GPIO pin Output Level */
  HAL_GPIO_WritePin(LD6_GPIO_Port, LD6_Pin, GPIO_PIN_SET);

  /*Configure GPIO pin Output Level */
  HAL_GPIO_WritePin(LCD_BL_GPIO_Port, LCD_BL_Pin, GPIO_PIN_RESET);

  /*Configure GPIO pin Output Level */
  HAL_GPIO_WritePin(LD7_GPIO_Port, LD7_Pin, GPIO_PIN_SET);

  /*Configure GPIO pins : VBUS_OTG_FS_Pin OTG_FS2_PSO_Pin */
  GPIO_InitStruct.Pin = VBUS_OTG_FS_Pin|OTG_FS2_PSO_Pin;
  GPIO_InitStruct.Mode = GPIO_MODE_OUTPUT_PP;
  GPIO_InitStruct.Pull = GPIO_NOPULL;
  GPIO_InitStruct.Speed = GPIO_SPEED_FREQ_LOW;
  HAL_GPIO_Init(GPIOA, &GPIO_InitStruct);

  /*Configure GPIO pins : SPI_CS_Pin LD6_Pin */
  GPIO_InitStruct.Pin = SPI_CS_Pin|LD6_Pin;
  GPIO_InitStruct.Mode = GPIO_MODE_OUTPUT_PP;
  GPIO_InitStruct.Pull = GPIO_NOPULL;
  GPIO_InitStruct.Speed = GPIO_SPEED_FREQ_LOW;
  HAL_GPIO_Init(GPIOI, &GPIO_InitStruct);

  /*Configure GPIO pin : LCD_BL_Pin */
  GPIO_InitStruct.Pin = LCD_BL_Pin;
  GPIO_InitStruct.Mode = GPIO_MODE_OUTPUT_PP;
  GPIO_InitStruct.Pull = GPIO_NOPULL;
  GPIO_InitStruct.Speed = GPIO_SPEED_FREQ_LOW;
  HAL_GPIO_Init(LCD_BL_GPIO_Port, &GPIO_InitStruct);

  /*Configure GPIO pin : SPI_HS_Pin */
  GPIO_InitStruct.Pin = SPI_HS_Pin;
  GPIO_InitStruct.Mode = GPIO_MODE_IT_RISING_FALLING;
  GPIO_InitStruct.Pull = GPIO_PULLDOWN;
  HAL_GPIO_Init(SPI_HS_GPIO_Port, &GPIO_InitStruct);

  /*Configure GPIO pin : LD7_Pin */
  GPIO_InitStruct.Pin = LD7_Pin;
  GPIO_InitStruct.Mode = GPIO_MODE_OUTPUT_PP;
  GPIO_InitStruct.Pull = GPIO_NOPULL;
  GPIO_InitStruct.Speed = GPIO_SPEED_FREQ_LOW;
  HAL_GPIO_Init(LD7_GPIO_Port, &GPIO_InitStruct);

  /* EXTI interrupt init*/
  HAL_NVIC_SetPriority(EXTI4_IRQn, 5, 0);
  HAL_NVIC_EnableIRQ(EXTI4_IRQn);

}

__weak void App_Task(void *argument)
{
  /* USER CODE BEGIN 5 */
  /* Infinite loop */
  for(;;) osDelay(1);
  /* USER CODE END 5 */
}

__weak void TouchGFX_Task(void *argument)
{
  /* USER CODE BEGIN TouchGFX_Task */
  /* Infinite loop */
  for(;;) osDelay(1);
  /* USER CODE END TouchGFX_Task */
}

/* MPU Configuration */

void MPU_Config(void)
{
  MPU_Region_InitTypeDef MPU_InitStruct = {0};

  /* Disables the MPU */
  HAL_MPU_Disable();

  /** Initializes and configures the Region and the memory to be protected
  */
  MPU_InitStruct.Enable = MPU_REGION_ENABLE;
  MPU_InitStruct.Number = MPU_REGION_NUMBER0;
  MPU_InitStruct.BaseAddress = 0xD0000000;
  MPU_InitStruct.Size = MPU_REGION_SIZE_1MB;
  MPU_InitStruct.SubRegionDisable = 0x0;
  MPU_InitStruct.TypeExtField = MPU_TEX_LEVEL0;
  MPU_InitStruct.AccessPermission = MPU_REGION_FULL_ACCESS;
  MPU_InitStruct.DisableExec = MPU_INSTRUCTION_ACCESS_DISABLE;
  MPU_InitStruct.IsShareable = MPU_ACCESS_NOT_SHAREABLE;
  MPU_InitStruct.IsCacheable = MPU_ACCESS_CACHEABLE;
  MPU_InitStruct.IsBufferable = MPU_ACCESS_BUFFERABLE;

  HAL_MPU_ConfigRegion(&MPU_InitStruct);

  /** Initializes and configures the Region and the memory to be protected
  */
  MPU_InitStruct.Number = MPU_REGION_NUMBER1;
  MPU_InitStruct.BaseAddress = 0x90000000;
  MPU_InitStruct.Size = MPU_REGION_SIZE_128MB;

  HAL_MPU_ConfigRegion(&MPU_InitStruct);
  /* Enables the MPU */
  HAL_MPU_Enable(MPU_PRIVILEGED_DEFAULT);

}

void HAL_TIM_PeriodElapsedCallback(TIM_HandleTypeDef *htim)
{
  if (htim->Instance == TIM6) {
    HAL_IncTick();
  }
}

void Error_Handler(void)
{
  /* USER CODE BEGIN Error_Handler_Debug */
  red_light_on();
  debug(0, "MAIN INITIALIZATION FAILED!");
  return;
  /* User can add his own implementation to report the HAL error return state */
  while (1) osDelay(1);
  /* USER CODE END Error_Handler_Debug */
}
